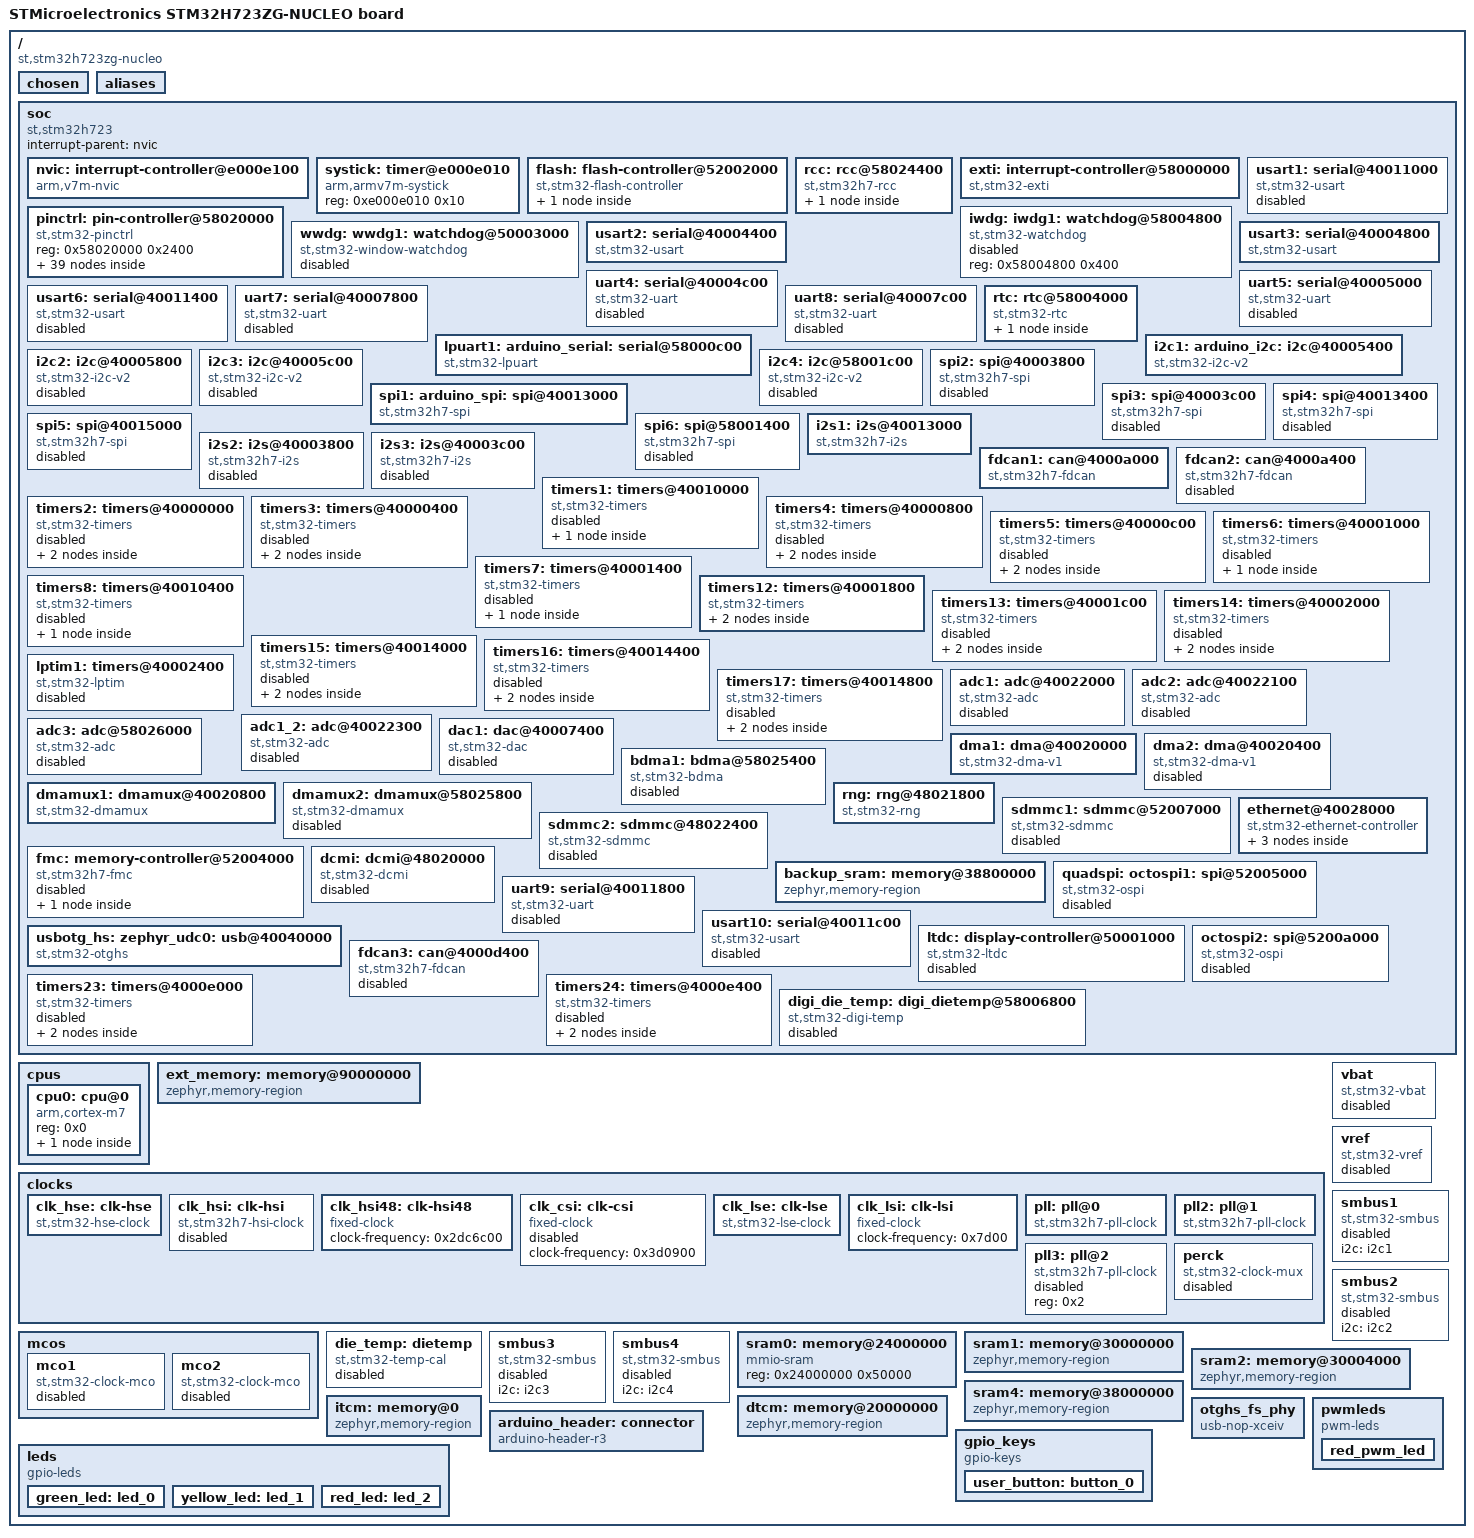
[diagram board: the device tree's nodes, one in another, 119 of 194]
/dts-v1/;

/* node '/' defined in zephyr\dts\common\skeleton.dtsi:9 */
/ {
	#address-cells = < 0x1 >;                              /* in zephyr\dts\common\skeleton.dtsi:10 */
	#size-cells = < 0x1 >;                                 /* in zephyr\dts\common\skeleton.dtsi:11 */
	model = "STMicroelectronics STM32H723ZG-NUCLEO board"; /* in zephyr\boards\st\nucleo_h723zg\nucleo_h723zg.dts:18 */
	compatible = "st,stm32h723zg-nucleo";                  /* in zephyr\boards\st\nucleo_h723zg\nucleo_h723zg.dts:19 */

	/* node '/chosen' defined in zephyr\dts\common\skeleton.dtsi:12 */
	chosen {
		zephyr,entropy = &rng;            /* in zephyr\dts\arm\st\h7\stm32h7.dtsi:27 */
		zephyr,flash-controller = &flash; /* in zephyr\dts\arm\st\h7\stm32h7.dtsi:28 */
		zephyr,console = &usart3;         /* in zephyr\boards\st\nucleo_h723zg\nucleo_h723zg.dts:22 */
		zephyr,shell-uart = &usart3;      /* in zephyr\boards\st\nucleo_h723zg\nucleo_h723zg.dts:23 */
		zephyr,dtcm = &dtcm;              /* in zephyr\boards\st\nucleo_h723zg\nucleo_h723zg.dts:24 */
		zephyr,sram = &sram0;             /* in zephyr\boards\st\nucleo_h723zg\nucleo_h723zg.dts:25 */
		zephyr,flash = &flash0;           /* in zephyr\boards\st\nucleo_h723zg\nucleo_h723zg.dts:26 */
		zephyr,canbus = &fdcan1;          /* in zephyr\boards\st\nucleo_h723zg\nucleo_h723zg.dts:27 */
	};

	/* node '/aliases' defined in zephyr\dts\common\skeleton.dtsi:13 */
	aliases {
		led0 = &green_led;       /* in zephyr\boards\st\nucleo_h723zg\nucleo_h723zg.dts:69 */
		led1 = &yellow_led;      /* in zephyr\boards\st\nucleo_h723zg\nucleo_h723zg.dts:70 */
		led2 = &red_led;         /* in zephyr\boards\st\nucleo_h723zg\nucleo_h723zg.dts:71 */
		pwm-led0 = &red_pwm_led; /* in zephyr\boards\st\nucleo_h723zg\nucleo_h723zg.dts:72 */
		sw0 = &user_button;      /* in zephyr\boards\st\nucleo_h723zg\nucleo_h723zg.dts:73 */
	};

	/* node '/soc' defined in zephyr\dts\arm\armv7-m.dtsi:6 */
	soc {
		#address-cells = < 0x1 >;     /* in zephyr\dts\arm\armv7-m.dtsi:7 */
		#size-cells = < 0x1 >;        /* in zephyr\dts\arm\armv7-m.dtsi:8 */
		interrupt-parent = < &nvic >; /* in zephyr\dts\arm\armv7-m.dtsi:10 */
		ranges;                       /* in zephyr\dts\arm\armv7-m.dtsi:11 */
		compatible = "st,stm32h723",
		             "st,stm32h7",
		             "simple-bus";    /* in zephyr\dts\arm\st\h7\stm32h723.dtsi:15 */

		/* node '/soc/interrupt-controller@e000e100' defined in zephyr\dts\arm\armv7-m.dtsi:13 */
		nvic: interrupt-controller@e000e100 {
			#address-cells = < 0x1 >;            /* in zephyr\dts\arm\armv7-m.dtsi:14 */
			compatible = "arm,v7m-nvic";         /* in zephyr\dts\arm\armv7-m.dtsi:15 */
			reg = < 0xe000e100 0xc00 >;          /* in zephyr\dts\arm\armv7-m.dtsi:16 */
			interrupt-controller;                /* in zephyr\dts\arm\armv7-m.dtsi:17 */
			#interrupt-cells = < 0x2 >;          /* in zephyr\dts\arm\armv7-m.dtsi:18 */
			arm,num-irq-priority-bits = < 0x4 >; /* in zephyr\dts\arm\st\h7\stm32h7.dtsi:1157 */
			phandle = < 0x1 >;                   /* in zephyr\dts\arm\armv7-m.dtsi:10 */
		};

		/* node '/soc/timer@e000e010' defined in zephyr\dts\arm\armv7-m.dtsi:21 */
		systick: timer@e000e010 {
			compatible = "arm,armv7m-systick"; /* in zephyr\dts\arm\armv7-m.dtsi:22 */
			reg = < 0xe000e010 0x10 >;         /* in zephyr\dts\arm\armv7-m.dtsi:23 */
		};

		/* node '/soc/flash-controller@52002000' defined in zephyr\dts\arm\st\h7\stm32h7.dtsi:144 */
		flash: flash-controller@52002000 {
			compatible = "st,stm32-flash-controller",
			             "st,stm32h7-flash-controller"; /* in zephyr\dts\arm\st\h7\stm32h7.dtsi:145 */
			reg = < 0x52002000 0x400 >;                 /* in zephyr\dts\arm\st\h7\stm32h7.dtsi:146 */
			interrupts = < 0x4 0x0 >;                   /* in zephyr\dts\arm\st\h7\stm32h7.dtsi:147 */
			#address-cells = < 0x1 >;                   /* in zephyr\dts\arm\st\h7\stm32h7.dtsi:149 */
			#size-cells = < 0x1 >;                      /* in zephyr\dts\arm\st\h7\stm32h7.dtsi:150 */

			/* node '/soc/flash-controller@52002000/flash@8000000' defined in zephyr\dts\arm\st\h7\stm32h723.dtsi:18 */
			flash0: flash@8000000 {
				compatible = "st,stm32-nv-flash",
				             "soc-nv-flash";      /* in zephyr\dts\arm\st\h7\stm32h723.dtsi:19 */
				write-block-size = < 0x20 >;      /* in zephyr\dts\arm\st\h7\stm32h723.dtsi:20 */
				erase-block-size = < 0x20000 >;   /* in zephyr\dts\arm\st\h7\stm32h723.dtsi:21 */
				max-erase-time = < 0xfa0 >;       /* in zephyr\dts\arm\st\h7\stm32h723.dtsi:23 */
				reg = < 0x8000000 0x100000 >;     /* in zephyr\dts\arm\st\h7\stm32h723Xg.dtsi:14 */
			};
		};

		/* node '/soc/rcc@58024400' defined in zephyr\dts\arm\st\h7\stm32h7.dtsi:153 */
		rcc: rcc@58024400 {
			compatible = "st,stm32h7-rcc";    /* in zephyr\dts\arm\st\h7\stm32h7.dtsi:154 */
			#clock-cells = < 0x2 >;           /* in zephyr\dts\arm\st\h7\stm32h7.dtsi:155 */
			reg = < 0x58024400 0x400 >;       /* in zephyr\dts\arm\st\h7\stm32h7.dtsi:156 */
			clocks = < &pll >;                /* in zephyr\boards\st\nucleo_h723zg\nucleo_h723zg.dts:116 */
			clock-frequency = < 0x20c85580 >; /* in zephyr\boards\st\nucleo_h723zg\nucleo_h723zg.dts:117 */
			d1cpre = < 0x1 >;                 /* in zephyr\boards\st\nucleo_h723zg\nucleo_h723zg.dts:118 */
			hpre = < 0x2 >;                   /* in zephyr\boards\st\nucleo_h723zg\nucleo_h723zg.dts:119 */
			d1ppre = < 0x2 >;                 /* in zephyr\boards\st\nucleo_h723zg\nucleo_h723zg.dts:120 */
			d2ppre1 = < 0x2 >;                /* in zephyr\boards\st\nucleo_h723zg\nucleo_h723zg.dts:121 */
			d2ppre2 = < 0x2 >;                /* in zephyr\boards\st\nucleo_h723zg\nucleo_h723zg.dts:122 */
			d3ppre = < 0x2 >;                 /* in zephyr\boards\st\nucleo_h723zg\nucleo_h723zg.dts:123 */
			phandle = < 0x3 >;                /* in zephyr\dts\arm\st\h7\stm32h7.dtsi:170 */

			/* node '/soc/rcc@58024400/reset-controller' defined in zephyr\dts\arm\st\h7\stm32h7.dtsi:158 */
			rctl: reset-controller {
				compatible = "st,stm32-rcc-rctl"; /* in zephyr\dts\arm\st\h7\stm32h7.dtsi:159 */
				#reset-cells = < 0x1 >;           /* in zephyr\dts\arm\st\h7\stm32h7.dtsi:160 */
				phandle = < 0x4 >;                /* in zephyr\dts\arm\st\h7\stm32h7.dtsi:293 */
			};
		};

		/* node '/soc/interrupt-controller@58000000' defined in zephyr\dts\arm\st\h7\stm32h7.dtsi:164 */
		exti: interrupt-controller@58000000 {
			compatible = "st,stm32-exti";  /* in zephyr\dts\arm\st\h7\stm32h7.dtsi:165 */
			interrupt-controller;          /* in zephyr\dts\arm\st\h7\stm32h7.dtsi:166 */
			#interrupt-cells = < 0x1 >;    /* in zephyr\dts\arm\st\h7\stm32h7.dtsi:167 */
			#address-cells = < 0x1 >;      /* in zephyr\dts\arm\st\h7\stm32h7.dtsi:168 */
			reg = < 0x58000000 0x400 >;    /* in zephyr\dts\arm\st\h7\stm32h7.dtsi:169 */
			clocks = < &rcc 0xf4 0x2 >;    /* in zephyr\dts\arm\st\h7\stm32h7.dtsi:170 */
			num-lines = < 0x60 >;          /* in zephyr\dts\arm\st\h7\stm32h7.dtsi:171 */
			interrupts = < 0x6 0x0 >,
			             < 0x7 0x0 >,
			             < 0x8 0x0 >,
			             < 0x9 0x0 >,
			             < 0xa 0x0 >,
			             < 0x17 0x0 >,
			             < 0x28 0x0 >;     /* in zephyr\dts\arm\st\h7\stm32h7.dtsi:172 */
			interrupt-names = "line0",
			                  "line1",
			                  "line2",
			                  "line3",
			                  "line4",
			                  "line5-9",
			                  "line10-15"; /* in zephyr\dts\arm\st\h7\stm32h7.dtsi:174 */
			line-ranges = < 0x0 0x1 >,
			              < 0x1 0x1 >,
			              < 0x2 0x1 >,
			              < 0x3 0x1 >,
			              < 0x4 0x1 >,
			              < 0x5 0x5 >,
			              < 0xa 0x6 >;     /* in zephyr\dts\arm\st\h7\stm32h7.dtsi:176 */
		};

		/* node '/soc/pin-controller@58020000' defined in zephyr\dts\arm\st\h7\stm32h7.dtsi:180 */
		pinctrl: pin-controller@58020000 {
			compatible = "st,stm32-pinctrl"; /* in zephyr\dts\arm\st\h7\stm32h7.dtsi:181 */
			#address-cells = < 0x1 >;        /* in zephyr\dts\arm\st\h7\stm32h7.dtsi:182 */
			#size-cells = < 0x1 >;           /* in zephyr\dts\arm\st\h7\stm32h7.dtsi:183 */
			reg = < 0x58020000 0x2400 >;     /* in zephyr\dts\arm\st\h7\stm32h7.dtsi:184 */

			/* node '/soc/pin-controller@58020000/gpio@58020000' defined in zephyr\dts\arm\st\h7\stm32h7.dtsi:186 */
			gpioa: gpio@58020000 {
				compatible = "st,stm32-gpio"; /* in zephyr\dts\arm\st\h7\stm32h7.dtsi:187 */
				gpio-controller;              /* in zephyr\dts\arm\st\h7\stm32h7.dtsi:188 */
				#gpio-cells = < 0x2 >;        /* in zephyr\dts\arm\st\h7\stm32h7.dtsi:189 */
				reg = < 0x58020000 0x400 >;   /* in zephyr\dts\arm\st\h7\stm32h7.dtsi:190 */
				clocks = < &rcc 0xe0 0x1 >;   /* in zephyr\dts\arm\st\h7\stm32h7.dtsi:191 */
				phandle = < 0x2c >;           /* in zephyr\boards\st\nucleo_h723zg\arduino_r3_connector.dtsi:12 */
			};

			/* node '/soc/pin-controller@58020000/gpio@58020400' defined in zephyr\dts\arm\st\h7\stm32h7.dtsi:194 */
			gpiob: gpio@58020400 {
				compatible = "st,stm32-gpio"; /* in zephyr\dts\arm\st\h7\stm32h7.dtsi:195 */
				gpio-controller;              /* in zephyr\dts\arm\st\h7\stm32h7.dtsi:196 */
				#gpio-cells = < 0x2 >;        /* in zephyr\dts\arm\st\h7\stm32h7.dtsi:197 */
				reg = < 0x58020400 0x400 >;   /* in zephyr\dts\arm\st\h7\stm32h7.dtsi:198 */
				clocks = < &rcc 0xe0 0x2 >;   /* in zephyr\dts\arm\st\h7\stm32h7.dtsi:199 */
				phandle = < 0x2e >;           /* in zephyr\boards\st\nucleo_h723zg\arduino_r3_connector.dtsi:12 */
			};

			/* node '/soc/pin-controller@58020000/gpio@58020800' defined in zephyr\dts\arm\st\h7\stm32h7.dtsi:202 */
			gpioc: gpio@58020800 {
				compatible = "st,stm32-gpio"; /* in zephyr\dts\arm\st\h7\stm32h7.dtsi:203 */
				gpio-controller;              /* in zephyr\dts\arm\st\h7\stm32h7.dtsi:204 */
				#gpio-cells = < 0x2 >;        /* in zephyr\dts\arm\st\h7\stm32h7.dtsi:205 */
				reg = < 0x58020800 0x400 >;   /* in zephyr\dts\arm\st\h7\stm32h7.dtsi:206 */
				clocks = < &rcc 0xe0 0x4 >;   /* in zephyr\dts\arm\st\h7\stm32h7.dtsi:207 */
				phandle = < 0x2d >;           /* in zephyr\boards\st\nucleo_h723zg\arduino_r3_connector.dtsi:12 */
			};

			/* node '/soc/pin-controller@58020000/gpio@58020C00' defined in zephyr\dts\arm\st\h7\stm32h7.dtsi:210 */
			gpiod: gpio@58020C00 {
				compatible = "st,stm32-gpio"; /* in zephyr\dts\arm\st\h7\stm32h7.dtsi:211 */
				gpio-controller;              /* in zephyr\dts\arm\st\h7\stm32h7.dtsi:212 */
				#gpio-cells = < 0x2 >;        /* in zephyr\dts\arm\st\h7\stm32h7.dtsi:213 */
				reg = < 0x58020c00 0x400 >;   /* in zephyr\dts\arm\st\h7\stm32h7.dtsi:214 */
				clocks = < &rcc 0xe0 0x8 >;   /* in zephyr\dts\arm\st\h7\stm32h7.dtsi:215 */
				phandle = < 0x10 >;           /* in zephyr\boards\st\nucleo_h723zg\nucleo_h723zg.dts:157 */
			};

			/* node '/soc/pin-controller@58020000/gpio@58021000' defined in zephyr\dts\arm\st\h7\stm32h7.dtsi:218 */
			gpioe: gpio@58021000 {
				compatible = "st,stm32-gpio"; /* in zephyr\dts\arm\st\h7\stm32h7.dtsi:219 */
				gpio-controller;              /* in zephyr\dts\arm\st\h7\stm32h7.dtsi:220 */
				#gpio-cells = < 0x2 >;        /* in zephyr\dts\arm\st\h7\stm32h7.dtsi:221 */
				reg = < 0x58021000 0x400 >;   /* in zephyr\dts\arm\st\h7\stm32h7.dtsi:222 */
				clocks = < &rcc 0xe0 0x10 >;  /* in zephyr\dts\arm\st\h7\stm32h7.dtsi:223 */
				phandle = < 0x31 >;           /* in zephyr\boards\st\nucleo_h723zg\arduino_r3_connector.dtsi:12 */
			};

			/* node '/soc/pin-controller@58020000/gpio@58021400' defined in zephyr\dts\arm\st\h7\stm32h7.dtsi:226 */
			gpiof: gpio@58021400 {
				compatible = "st,stm32-gpio"; /* in zephyr\dts\arm\st\h7\stm32h7.dtsi:227 */
				gpio-controller;              /* in zephyr\dts\arm\st\h7\stm32h7.dtsi:228 */
				#gpio-cells = < 0x2 >;        /* in zephyr\dts\arm\st\h7\stm32h7.dtsi:229 */
				reg = < 0x58021400 0x400 >;   /* in zephyr\dts\arm\st\h7\stm32h7.dtsi:230 */
				clocks = < &rcc 0xe0 0x20 >;  /* in zephyr\dts\arm\st\h7\stm32h7.dtsi:231 */
				phandle = < 0x2f >;           /* in zephyr\boards\st\nucleo_h723zg\arduino_r3_connector.dtsi:12 */
			};

			/* node '/soc/pin-controller@58020000/gpio@58021800' defined in zephyr\dts\arm\st\h7\stm32h7.dtsi:234 */
			gpiog: gpio@58021800 {
				compatible = "st,stm32-gpio"; /* in zephyr\dts\arm\st\h7\stm32h7.dtsi:235 */
				gpio-controller;              /* in zephyr\dts\arm\st\h7\stm32h7.dtsi:236 */
				#gpio-cells = < 0x2 >;        /* in zephyr\dts\arm\st\h7\stm32h7.dtsi:237 */
				reg = < 0x58021800 0x400 >;   /* in zephyr\dts\arm\st\h7\stm32h7.dtsi:238 */
				clocks = < &rcc 0xe0 0x40 >;  /* in zephyr\dts\arm\st\h7\stm32h7.dtsi:239 */
				phandle = < 0x30 >;           /* in zephyr\boards\st\nucleo_h723zg\arduino_r3_connector.dtsi:12 */
			};

			/* node '/soc/pin-controller@58020000/gpio@58021C00' defined in zephyr\dts\arm\st\h7\stm32h7.dtsi:242 */
			gpioh: gpio@58021C00 {
				compatible = "st,stm32-gpio"; /* in zephyr\dts\arm\st\h7\stm32h7.dtsi:243 */
				gpio-controller;              /* in zephyr\dts\arm\st\h7\stm32h7.dtsi:244 */
				#gpio-cells = < 0x2 >;        /* in zephyr\dts\arm\st\h7\stm32h7.dtsi:245 */
				reg = < 0x58021c00 0x400 >;   /* in zephyr\dts\arm\st\h7\stm32h7.dtsi:246 */
				clocks = < &rcc 0xe0 0x80 >;  /* in zephyr\dts\arm\st\h7\stm32h7.dtsi:247 */
			};

			/* node '/soc/pin-controller@58020000/gpio@58022000' defined in zephyr\dts\arm\st\h7\stm32h7.dtsi:250 */
			gpioi: gpio@58022000 {
				compatible = "st,stm32-gpio"; /* in zephyr\dts\arm\st\h7\stm32h7.dtsi:251 */
				gpio-controller;              /* in zephyr\dts\arm\st\h7\stm32h7.dtsi:252 */
				#gpio-cells = < 0x2 >;        /* in zephyr\dts\arm\st\h7\stm32h7.dtsi:253 */
				reg = < 0x58022000 0x400 >;   /* in zephyr\dts\arm\st\h7\stm32h7.dtsi:254 */
				clocks = < &rcc 0xe0 0x100 >; /* in zephyr\dts\arm\st\h7\stm32h7.dtsi:255 */
			};

			/* node '/soc/pin-controller@58020000/gpio@58022400' defined in zephyr\dts\arm\st\h7\stm32h7.dtsi:258 */
			gpioj: gpio@58022400 {
				compatible = "st,stm32-gpio"; /* in zephyr\dts\arm\st\h7\stm32h7.dtsi:259 */
				gpio-controller;              /* in zephyr\dts\arm\st\h7\stm32h7.dtsi:260 */
				#gpio-cells = < 0x2 >;        /* in zephyr\dts\arm\st\h7\stm32h7.dtsi:261 */
				reg = < 0x58022400 0x400 >;   /* in zephyr\dts\arm\st\h7\stm32h7.dtsi:262 */
				clocks = < &rcc 0xe0 0x200 >; /* in zephyr\dts\arm\st\h7\stm32h7.dtsi:263 */
			};

			/* node '/soc/pin-controller@58020000/gpio@58022800' defined in zephyr\dts\arm\st\h7\stm32h7.dtsi:266 */
			gpiok: gpio@58022800 {
				compatible = "st,stm32-gpio"; /* in zephyr\dts\arm\st\h7\stm32h7.dtsi:267 */
				gpio-controller;              /* in zephyr\dts\arm\st\h7\stm32h7.dtsi:268 */
				#gpio-cells = < 0x2 >;        /* in zephyr\dts\arm\st\h7\stm32h7.dtsi:269 */
				reg = < 0x58022800 0x400 >;   /* in zephyr\dts\arm\st\h7\stm32h7.dtsi:270 */
				clocks = < &rcc 0xe0 0x400 >; /* in zephyr\dts\arm\st\h7\stm32h7.dtsi:271 */
			};

			/* node '/soc/pin-controller@58020000/eth_ref_clk_pa1' defined in modules\hal\stm32\dts\st\h7\stm32h723zgtx-pinctrl.dtsi:1148 */
			eth_ref_clk_pa1: eth_ref_clk_pa1 {
				pinmux = < 0x2b >;             /* in modules\hal\stm32\dts\st\h7\stm32h723zgtx-pinctrl.dtsi:1149 */
				slew-rate = "very-high-speed"; /* in modules\hal\stm32\dts\st\h7\stm32h723zgtx-pinctrl.dtsi:1150 */
				phandle = < 0x18 >;            /* in zephyr\boards\st\nucleo_h723zg\nucleo_h723zg.dts:184 */
			};

			/* node '/soc/pin-controller@58020000/eth_mdio_pa2' defined in modules\hal\stm32\dts\st\h7\stm32h723zgtx-pinctrl.dtsi:1158 */
			eth_mdio_pa2: eth_mdio_pa2 {
				pinmux = < 0x4b >;             /* in modules\hal\stm32\dts\st\h7\stm32h723zgtx-pinctrl.dtsi:1159 */
				slew-rate = "very-high-speed"; /* in modules\hal\stm32\dts\st\h7\stm32h723zgtx-pinctrl.dtsi:1160 */
				phandle = < 0x20 >;            /* in zephyr\boards\st\nucleo_h723zg\nucleo_h723zg.dts:198 */
			};

			/* node '/soc/pin-controller@58020000/eth_crs_dv_pa7' defined in modules\hal\stm32\dts\st\h7\stm32h723zgtx-pinctrl.dtsi:1168 */
			eth_crs_dv_pa7: eth_crs_dv_pa7 {
				pinmux = < 0xeb >;             /* in modules\hal\stm32\dts\st\h7\stm32h723zgtx-pinctrl.dtsi:1169 */
				slew-rate = "very-high-speed"; /* in modules\hal\stm32\dts\st\h7\stm32h723zgtx-pinctrl.dtsi:1170 */
				phandle = < 0x19 >;            /* in zephyr\boards\st\nucleo_h723zg\nucleo_h723zg.dts:184 */
			};

			/* node '/soc/pin-controller@58020000/eth_txd1_pb13' defined in modules\hal\stm32\dts\st\h7\stm32h723zgtx-pinctrl.dtsi:1213 */
			eth_txd1_pb13: eth_txd1_pb13 {
				pinmux = < 0x3ab >;            /* in modules\hal\stm32\dts\st\h7\stm32h723zgtx-pinctrl.dtsi:1214 */
				slew-rate = "very-high-speed"; /* in modules\hal\stm32\dts\st\h7\stm32h723zgtx-pinctrl.dtsi:1215 */
				phandle = < 0x1e >;            /* in zephyr\boards\st\nucleo_h723zg\nucleo_h723zg.dts:184 */
			};

			/* node '/soc/pin-controller@58020000/eth_mdc_pc1' defined in modules\hal\stm32\dts\st\h7\stm32h723zgtx-pinctrl.dtsi:1218 */
			eth_mdc_pc1: eth_mdc_pc1 {
				pinmux = < 0x42b >;            /* in modules\hal\stm32\dts\st\h7\stm32h723zgtx-pinctrl.dtsi:1219 */
				slew-rate = "very-high-speed"; /* in modules\hal\stm32\dts\st\h7\stm32h723zgtx-pinctrl.dtsi:1220 */
				phandle = < 0x21 >;            /* in zephyr\boards\st\nucleo_h723zg\nucleo_h723zg.dts:198 */
			};

			/* node '/soc/pin-controller@58020000/eth_rxd0_pc4' defined in modules\hal\stm32\dts\st\h7\stm32h723zgtx-pinctrl.dtsi:1233 */
			eth_rxd0_pc4: eth_rxd0_pc4 {
				pinmux = < 0x48b >;            /* in modules\hal\stm32\dts\st\h7\stm32h723zgtx-pinctrl.dtsi:1234 */
				slew-rate = "very-high-speed"; /* in modules\hal\stm32\dts\st\h7\stm32h723zgtx-pinctrl.dtsi:1235 */
				phandle = < 0x1a >;            /* in zephyr\boards\st\nucleo_h723zg\nucleo_h723zg.dts:184 */
			};

			/* node '/soc/pin-controller@58020000/eth_rxd1_pc5' defined in modules\hal\stm32\dts\st\h7\stm32h723zgtx-pinctrl.dtsi:1238 */
			eth_rxd1_pc5: eth_rxd1_pc5 {
				pinmux = < 0x4ab >;            /* in modules\hal\stm32\dts\st\h7\stm32h723zgtx-pinctrl.dtsi:1239 */
				slew-rate = "very-high-speed"; /* in modules\hal\stm32\dts\st\h7\stm32h723zgtx-pinctrl.dtsi:1240 */
				phandle = < 0x1b >;            /* in zephyr\boards\st\nucleo_h723zg\nucleo_h723zg.dts:184 */
			};

			/* node '/soc/pin-controller@58020000/eth_tx_en_pg11' defined in modules\hal\stm32\dts\st\h7\stm32h723zgtx-pinctrl.dtsi:1253 */
			eth_tx_en_pg11: eth_tx_en_pg11 {
				pinmux = < 0xd6b >;            /* in modules\hal\stm32\dts\st\h7\stm32h723zgtx-pinctrl.dtsi:1254 */
				slew-rate = "very-high-speed"; /* in modules\hal\stm32\dts\st\h7\stm32h723zgtx-pinctrl.dtsi:1255 */
				phandle = < 0x1c >;            /* in zephyr\boards\st\nucleo_h723zg\nucleo_h723zg.dts:184 */
			};

			/* node '/soc/pin-controller@58020000/eth_txd0_pg13' defined in modules\hal\stm32\dts\st\h7\stm32h723zgtx-pinctrl.dtsi:1263 */
			eth_txd0_pg13: eth_txd0_pg13 {
				pinmux = < 0xdab >;            /* in modules\hal\stm32\dts\st\h7\stm32h723zgtx-pinctrl.dtsi:1264 */
				slew-rate = "very-high-speed"; /* in modules\hal\stm32\dts\st\h7\stm32h723zgtx-pinctrl.dtsi:1265 */
				phandle = < 0x1d >;            /* in zephyr\boards\st\nucleo_h723zg\nucleo_h723zg.dts:184 */
			};

			/* node '/soc/pin-controller@58020000/fdcan1_rx_pd0' defined in modules\hal\stm32\dts\st\h7\stm32h723zgtx-pinctrl.dtsi:1283 */
			fdcan1_rx_pd0: fdcan1_rx_pd0 {
				pinmux = < 0x609 >; /* in modules\hal\stm32\dts\st\h7\stm32h723zgtx-pinctrl.dtsi:1284 */
				phandle = < 0x15 >; /* in zephyr\boards\st\nucleo_h723zg\nucleo_h723zg.dts:218 */
			};

			/* node '/soc/pin-controller@58020000/fdcan1_tx_pd1' defined in modules\hal\stm32\dts\st\h7\stm32h723zgtx-pinctrl.dtsi:1317 */
			fdcan1_tx_pd1: fdcan1_tx_pd1 {
				pinmux = < 0x629 >; /* in modules\hal\stm32\dts\st\h7\stm32h723zgtx-pinctrl.dtsi:1318 */
				phandle = < 0x16 >; /* in zephyr\boards\st\nucleo_h723zg\nucleo_h723zg.dts:218 */
			};

			/* node '/soc/pin-controller@58020000/i2c1_scl_pb8' defined in modules\hal\stm32\dts\st\h7\stm32h723zgtx-pinctrl.dtsi:1843 */
			i2c1_scl_pb8: i2c1_scl_pb8 {
				pinmux = < 0x304 >; /* in modules\hal\stm32\dts\st\h7\stm32h723zgtx-pinctrl.dtsi:1844 */
				bias-pull-up;       /* in modules\hal\stm32\dts\st\h7\stm32h723zgtx-pinctrl.dtsi:1845 */
				drive-open-drain;   /* in modules\hal\stm32\dts\st\h7\stm32h723zgtx-pinctrl.dtsi:1846 */
				phandle = < 0xb >;  /* in zephyr\boards\st\nucleo_h723zg\nucleo_h723zg.dts:161 */
			};

			/* node '/soc/pin-controller@58020000/i2c1_sda_pb9' defined in modules\hal\stm32\dts\st\h7\stm32h723zgtx-pinctrl.dtsi:1917 */
			i2c1_sda_pb9: i2c1_sda_pb9 {
				pinmux = < 0x324 >; /* in modules\hal\stm32\dts\st\h7\stm32h723zgtx-pinctrl.dtsi:1918 */
				bias-pull-up;       /* in modules\hal\stm32\dts\st\h7\stm32h723zgtx-pinctrl.dtsi:1919 */
				drive-open-drain;   /* in modules\hal\stm32\dts\st\h7\stm32h723zgtx-pinctrl.dtsi:1920 */
				phandle = < 0xc >;  /* in zephyr\boards\st\nucleo_h723zg\nucleo_h723zg.dts:161 */
			};

			/* node '/soc/pin-controller@58020000/i2s1_ck_pa5' defined in modules\hal\stm32\dts\st\h7\stm32h723zgtx-pinctrl.dtsi:2042 */
			i2s1_ck_pa5: i2s1_ck_pa5 {
				pinmux = < 0xa5 >;             /* in modules\hal\stm32\dts\st\h7\stm32h723zgtx-pinctrl.dtsi:2043 */
				slew-rate = "very-high-speed"; /* in modules\hal\stm32\dts\st\h7\stm32h723zgtx-pinctrl.dtsi:2044 */
				phandle = < 0x11 >;            /* in template_zephyr\boards\nucleo_h723zg.overlay:12 */
			};

			/* node '/soc/pin-controller@58020000/i2s1_ws_pa4' defined in modules\hal\stm32\dts\st\h7\stm32h723zgtx-pinctrl.dtsi:2136 */
			i2s1_ws_pa4: i2s1_ws_pa4 {
				pinmux = < 0x85 >;  /* in modules\hal\stm32\dts\st\h7\stm32h723zgtx-pinctrl.dtsi:2137 */
				phandle = < 0x12 >; /* in template_zephyr\boards\nucleo_h723zg.overlay:12 */
			};

			/* node '/soc/pin-controller@58020000/sai1_sd_a_pb2' defined in modules\hal\stm32\dts\st\h7\stm32h723zgtx-pinctrl.dtsi:2809 */
			sai1_sd_a_pb2: sai1_sd_a_pb2 {
				pinmux = < 0x246 >; /* in modules\hal\stm32\dts\st\h7\stm32h723zgtx-pinctrl.dtsi:2810 */
				phandle = < 0x13 >; /* in template_zephyr\boards\nucleo_h723zg.overlay:12 */
			};

			/* node '/soc/pin-controller@58020000/spi1_miso_pa6' defined in modules\hal\stm32\dts\st\h7\stm32h723zgtx-pinctrl.dtsi:3253 */
			spi1_miso_pa6: spi1_miso_pa6 {
				pinmux = < 0xc5 >; /* in modules\hal\stm32\dts\st\h7\stm32h723zgtx-pinctrl.dtsi:3254 */
				bias-pull-down;    /* in modules\hal\stm32\dts\st\h7\stm32h723zgtx-pinctrl.dtsi:3255 */
				phandle = < 0xe >; /* in zephyr\boards\st\nucleo_h723zg\nucleo_h723zg.dts:155 */
			};

			/* node '/soc/pin-controller@58020000/spi1_mosi_pb5' defined in modules\hal\stm32\dts\st\h7\stm32h723zgtx-pinctrl.dtsi:3325 */
			spi1_mosi_pb5: spi1_mosi_pb5 {
				pinmux = < 0x2a5 >; /* in modules\hal\stm32\dts\st\h7\stm32h723zgtx-pinctrl.dtsi:3326 */
				bias-pull-down;     /* in modules\hal\stm32\dts\st\h7\stm32h723zgtx-pinctrl.dtsi:3327 */
				phandle = < 0xf >;  /* in zephyr\boards\st\nucleo_h723zg\nucleo_h723zg.dts:155 */
			};

			/* node '/soc/pin-controller@58020000/spi1_sck_pa5' defined in modules\hal\stm32\dts\st\h7\stm32h723zgtx-pinctrl.dtsi:3489 */
			spi1_sck_pa5: spi1_sck_pa5 {
				pinmux = < 0xa5 >;             /* in modules\hal\stm32\dts\st\h7\stm32h723zgtx-pinctrl.dtsi:3490 */
				bias-pull-down;                /* in modules\hal\stm32\dts\st\h7\stm32h723zgtx-pinctrl.dtsi:3491 */
				slew-rate = "very-high-speed"; /* in modules\hal\stm32\dts\st\h7\stm32h723zgtx-pinctrl.dtsi:3492 */
				phandle = < 0xd >;             /* in zephyr\boards\st\nucleo_h723zg\nucleo_h723zg.dts:155 */
			};

			/* node '/soc/pin-controller@58020000/tim12_ch1_pb14' defined in modules\hal\stm32\dts\st\h7\stm32h723zgtx-pinctrl.dtsi:3767 */
			tim12_ch1_pb14: tim12_ch1_pb14 {
				pinmux = < 0x3c2 >; /* in modules\hal\stm32\dts\st\h7\stm32h723zgtx-pinctrl.dtsi:3768 */
				phandle = < 0x17 >; /* in zephyr\boards\st\nucleo_h723zg\nucleo_h723zg.dts:177 */
			};

			/* node '/soc/pin-controller@58020000/lpuart1_rx_pb7' defined in modules\hal\stm32\dts\st\h7\stm32h723zgtx-pinctrl.dtsi:4303 */
			lpuart1_rx_pb7: lpuart1_rx_pb7 {
				pinmux = < 0x2e8 >; /* in modules\hal\stm32\dts\st\h7\stm32h723zgtx-pinctrl.dtsi:4304 */
				phandle = < 0xa >;  /* in zephyr\boards\st\nucleo_h723zg\nucleo_h723zg.dts:127 */
			};

			/* node '/soc/pin-controller@58020000/usart2_rx_pd6' defined in modules\hal\stm32\dts\st\h7\stm32h723zgtx-pinctrl.dtsi:4319 */
			usart2_rx_pd6: usart2_rx_pd6 {
				pinmux = < 0x6c7 >; /* in modules\hal\stm32\dts\st\h7\stm32h723zgtx-pinctrl.dtsi:4320 */
				phandle = < 0x6 >;  /* in zephyr\boards\st\nucleo_h723zg\nucleo_h723zg.dts:141 */
			};

			/* node '/soc/pin-controller@58020000/usart3_rx_pd9' defined in modules\hal\stm32\dts\st\h7\stm32h723zgtx-pinctrl.dtsi:4331 */
			usart3_rx_pd9: usart3_rx_pd9 {
				pinmux = < 0x727 >; /* in modules\hal\stm32\dts\st\h7\stm32h723zgtx-pinctrl.dtsi:4332 */
				phandle = < 0x8 >;  /* in zephyr\boards\st\nucleo_h723zg\nucleo_h723zg.dts:134 */
			};

			/* node '/soc/pin-controller@58020000/lpuart1_tx_pb6' defined in modules\hal\stm32\dts\st\h7\stm32h723zgtx-pinctrl.dtsi:4425 */
			lpuart1_tx_pb6: lpuart1_tx_pb6 {
				pinmux = < 0x2c8 >; /* in modules\hal\stm32\dts\st\h7\stm32h723zgtx-pinctrl.dtsi:4426 */
				bias-pull-up;       /* in modules\hal\stm32\dts\st\h7\stm32h723zgtx-pinctrl.dtsi:4427 */
				phandle = < 0x9 >;  /* in zephyr\boards\st\nucleo_h723zg\nucleo_h723zg.dts:127 */
			};

			/* node '/soc/pin-controller@58020000/usart2_tx_pd5' defined in modules\hal\stm32\dts\st\h7\stm32h723zgtx-pinctrl.dtsi:4445 */
			usart2_tx_pd5: usart2_tx_pd5 {
				pinmux = < 0x6a7 >; /* in modules\hal\stm32\dts\st\h7\stm32h723zgtx-pinctrl.dtsi:4446 */
				bias-pull-up;       /* in modules\hal\stm32\dts\st\h7\stm32h723zgtx-pinctrl.dtsi:4447 */
				phandle = < 0x5 >;  /* in zephyr\boards\st\nucleo_h723zg\nucleo_h723zg.dts:141 */
			};

			/* node '/soc/pin-controller@58020000/usart3_tx_pd8' defined in modules\hal\stm32\dts\st\h7\stm32h723zgtx-pinctrl.dtsi:4460 */
			usart3_tx_pd8: usart3_tx_pd8 {
				pinmux = < 0x707 >; /* in modules\hal\stm32\dts\st\h7\stm32h723zgtx-pinctrl.dtsi:4461 */
				bias-pull-up;       /* in modules\hal\stm32\dts\st\h7\stm32h723zgtx-pinctrl.dtsi:4462 */
				phandle = < 0x7 >;  /* in zephyr\boards\st\nucleo_h723zg\nucleo_h723zg.dts:134 */
			};

			/* node '/soc/pin-controller@58020000/usb_otg_hs_dm_pa11' defined in modules\hal\stm32\dts\st\h7\stm32h723zgtx-pinctrl.dtsi:4564 */
			usb_otg_hs_dm_pa11: usb_otg_hs_dm_pa11 {
				pinmux = < 0x170 >; /* in modules\hal\stm32\dts\st\h7\stm32h723zgtx-pinctrl.dtsi:4565 */
				phandle = < 0x24 >; /* in zephyr\boards\st\nucleo_h723zg\nucleo_h723zg.dts:208 */
			};

			/* node '/soc/pin-controller@58020000/usb_otg_hs_dp_pa12' defined in modules\hal\stm32\dts\st\h7\stm32h723zgtx-pinctrl.dtsi:4568 */
			usb_otg_hs_dp_pa12: usb_otg_hs_dp_pa12 {
				pinmux = < 0x190 >; /* in modules\hal\stm32\dts\st\h7\stm32h723zgtx-pinctrl.dtsi:4569 */
				phandle = < 0x25 >; /* in zephyr\boards\st\nucleo_h723zg\nucleo_h723zg.dts:208 */
			};
		};

		/* node '/soc/watchdog@58004800' defined in zephyr\dts\arm\st\h7\stm32h7.dtsi:275 */
		iwdg: iwdg1: watchdog@58004800 {
			compatible = "st,stm32-watchdog"; /* in zephyr\dts\arm\st\h7\stm32h7.dtsi:276 */
			reg = < 0x58004800 0x400 >;       /* in zephyr\dts\arm\st\h7\stm32h7.dtsi:277 */
			status = "disabled";              /* in zephyr\dts\arm\st\h7\stm32h7.dtsi:278 */
		};

		/* node '/soc/watchdog@50003000' defined in zephyr\dts\arm\st\h7\stm32h7.dtsi:281 */
		wwdg: wwdg1: watchdog@50003000 {
			compatible = "st,stm32-window-watchdog"; /* in zephyr\dts\arm\st\h7\stm32h7.dtsi:282 */
			reg = < 0x50003000 0x1000 >;             /* in zephyr\dts\arm\st\h7\stm32h7.dtsi:283 */
			clocks = < &rcc 0xe4 0x40 >;             /* in zephyr\dts\arm\st\h7\stm32h7.dtsi:284 */
			interrupts = < 0x0 0x7 >;                /* in zephyr\dts\arm\st\h7\stm32h7.dtsi:285 */
			status = "disabled";                     /* in zephyr\dts\arm\st\h7\stm32h7.dtsi:286 */
		};

		/* node '/soc/serial@40011000' defined in zephyr\dts\arm\st\h7\stm32h7.dtsi:289 */
		usart1: serial@40011000 {
			compatible = "st,stm32-usart",
			             "st,stm32-uart";  /* in zephyr\dts\arm\st\h7\stm32h7.dtsi:290 */
			reg = < 0x40011000 0x400 >;    /* in zephyr\dts\arm\st\h7\stm32h7.dtsi:291 */
			clocks = < &rcc 0xf0 0x10 >;   /* in zephyr\dts\arm\st\h7\stm32h7.dtsi:292 */
			resets = < &rctl 0x1304 >;     /* in zephyr\dts\arm\st\h7\stm32h7.dtsi:293 */
			interrupts = < 0x25 0x0 >;     /* in zephyr\dts\arm\st\h7\stm32h7.dtsi:294 */
			status = "disabled";           /* in zephyr\dts\arm\st\h7\stm32h7.dtsi:295 */
		};

		/* node '/soc/serial@40004400' defined in zephyr\dts\arm\st\h7\stm32h7.dtsi:297 */
		usart2: serial@40004400 {
			compatible = "st,stm32-usart",
			             "st,stm32-uart";                  /* in zephyr\dts\arm\st\h7\stm32h7.dtsi:298 */
			reg = < 0x40004400 0x400 >;                    /* in zephyr\dts\arm\st\h7\stm32h7.dtsi:299 */
			clocks = < &rcc 0xe8 0x20000 >;                /* in zephyr\dts\arm\st\h7\stm32h7.dtsi:300 */
			resets = < &rctl 0x1211 >;                     /* in zephyr\dts\arm\st\h7\stm32h7.dtsi:301 */
			interrupts = < 0x26 0x0 >;                     /* in zephyr\dts\arm\st\h7\stm32h7.dtsi:302 */
			pinctrl-0 = < &usart2_tx_pd5 &usart2_rx_pd6 >; /* in zephyr\boards\st\nucleo_h723zg\nucleo_h723zg.dts:141 */
			pinctrl-names = "default";                     /* in zephyr\boards\st\nucleo_h723zg\nucleo_h723zg.dts:142 */
			current-speed = < 0x1c200 >;                   /* in zephyr\boards\st\nucleo_h723zg\nucleo_h723zg.dts:143 */
			status = "okay";                               /* in zephyr\boards\st\nucleo_h723zg\nucleo_h723zg.dts:144 */
		};

		/* node '/soc/serial@40004800' defined in zephyr\dts\arm\st\h7\stm32h7.dtsi:305 */
		usart3: serial@40004800 {
			compatible = "st,stm32-usart",
			             "st,stm32-uart";                  /* in zephyr\dts\arm\st\h7\stm32h7.dtsi:306 */
			reg = < 0x40004800 0x400 >;                    /* in zephyr\dts\arm\st\h7\stm32h7.dtsi:307 */
			clocks = < &rcc 0xe8 0x40000 >;                /* in zephyr\dts\arm\st\h7\stm32h7.dtsi:308 */
			resets = < &rctl 0x1212 >;                     /* in zephyr\dts\arm\st\h7\stm32h7.dtsi:309 */
			interrupts = < 0x27 0x0 >;                     /* in zephyr\dts\arm\st\h7\stm32h7.dtsi:310 */
			pinctrl-0 = < &usart3_tx_pd8 &usart3_rx_pd9 >; /* in zephyr\boards\st\nucleo_h723zg\nucleo_h723zg.dts:134 */
			pinctrl-names = "default";                     /* in zephyr\boards\st\nucleo_h723zg\nucleo_h723zg.dts:135 */
			status = "okay";                               /* in template_zephyr\boards\nucleo_h723zg.overlay:21 */
			current-speed = < 0x1c200 >;                   /* in template_zephyr\boards\nucleo_h723zg.overlay:22 */
		};

		/* node '/soc/serial@40004c00' defined in zephyr\dts\arm\st\h7\stm32h7.dtsi:313 */
		uart4: serial@40004c00 {
			compatible = "st,stm32-uart";   /* in zephyr\dts\arm\st\h7\stm32h7.dtsi:314 */
			reg = < 0x40004c00 0x400 >;     /* in zephyr\dts\arm\st\h7\stm32h7.dtsi:315 */
			clocks = < &rcc 0xe8 0x80000 >; /* in zephyr\dts\arm\st\h7\stm32h7.dtsi:316 */
			resets = < &rctl 0x1213 >;      /* in zephyr\dts\arm\st\h7\stm32h7.dtsi:317 */
			interrupts = < 0x34 0x0 >;      /* in zephyr\dts\arm\st\h7\stm32h7.dtsi:318 */
			status = "disabled";            /* in zephyr\dts\arm\st\h7\stm32h7.dtsi:319 */
		};

		/* node '/soc/serial@40005000' defined in zephyr\dts\arm\st\h7\stm32h7.dtsi:321 */
		uart5: serial@40005000 {
			compatible = "st,stm32-uart";    /* in zephyr\dts\arm\st\h7\stm32h7.dtsi:322 */
			reg = < 0x40005000 0x400 >;      /* in zephyr\dts\arm\st\h7\stm32h7.dtsi:323 */
			clocks = < &rcc 0xe8 0x100000 >; /* in zephyr\dts\arm\st\h7\stm32h7.dtsi:324 */
			resets = < &rctl 0x1214 >;       /* in zephyr\dts\arm\st\h7\stm32h7.dtsi:325 */
			interrupts = < 0x35 0x0 >;       /* in zephyr\dts\arm\st\h7\stm32h7.dtsi:326 */
			status = "disabled";             /* in zephyr\dts\arm\st\h7\stm32h7.dtsi:327 */
		};

		/* node '/soc/serial@40011400' defined in zephyr\dts\arm\st\h7\stm32h7.dtsi:329 */
		usart6: serial@40011400 {
			compatible = "st,stm32-usart",
			             "st,stm32-uart";  /* in zephyr\dts\arm\st\h7\stm32h7.dtsi:330 */
			reg = < 0x40011400 0x400 >;    /* in zephyr\dts\arm\st\h7\stm32h7.dtsi:331 */
			clocks = < &rcc 0xf0 0x20 >;   /* in zephyr\dts\arm\st\h7\stm32h7.dtsi:332 */
			resets = < &rctl 0x1305 >;     /* in zephyr\dts\arm\st\h7\stm32h7.dtsi:333 */
			interrupts = < 0x47 0x0 >;     /* in zephyr\dts\arm\st\h7\stm32h7.dtsi:334 */
			status = "disabled";           /* in zephyr\dts\arm\st\h7\stm32h7.dtsi:335 */
		};

		/* node '/soc/serial@40007800' defined in zephyr\dts\arm\st\h7\stm32h7.dtsi:337 */
		uart7: serial@40007800 {
			compatible = "st,stm32-uart";      /* in zephyr\dts\arm\st\h7\stm32h7.dtsi:338 */
			reg = < 0x40007800 0x400 >;        /* in zephyr\dts\arm\st\h7\stm32h7.dtsi:339 */
			clocks = < &rcc 0xe8 0x40000000 >; /* in zephyr\dts\arm\st\h7\stm32h7.dtsi:340 */
			resets = < &rctl 0x121e >;         /* in zephyr\dts\arm\st\h7\stm32h7.dtsi:341 */
			interrupts = < 0x52 0x0 >;         /* in zephyr\dts\arm\st\h7\stm32h7.dtsi:342 */
			status = "disabled";               /* in zephyr\dts\arm\st\h7\stm32h7.dtsi:343 */
		};

		/* node '/soc/serial@40007c00' defined in zephyr\dts\arm\st\h7\stm32h7.dtsi:345 */
		uart8: serial@40007c00 {
			compatible = "st,stm32-uart";      /* in zephyr\dts\arm\st\h7\stm32h7.dtsi:346 */
			reg = < 0x40007c00 0x400 >;        /* in zephyr\dts\arm\st\h7\stm32h7.dtsi:347 */
			clocks = < &rcc 0xe8 0x80000000 >; /* in zephyr\dts\arm\st\h7\stm32h7.dtsi:348 */
			resets = < &rctl 0x121f >;         /* in zephyr\dts\arm\st\h7\stm32h7.dtsi:349 */
			interrupts = < 0x53 0x0 >;         /* in zephyr\dts\arm\st\h7\stm32h7.dtsi:350 */
			status = "disabled";               /* in zephyr\dts\arm\st\h7\stm32h7.dtsi:351 */
		};

		/* node '/soc/serial@58000c00' defined in zephyr\dts\arm\st\h7\stm32h7.dtsi:354 */
		lpuart1: arduino_serial: serial@58000c00 {
			compatible = "st,stm32-lpuart",
			             "st,stm32-uart";                    /* in zephyr\dts\arm\st\h7\stm32h7.dtsi:355 */
			reg = < 0x58000c00 0x400 >;                      /* in zephyr\dts\arm\st\h7\stm32h7.dtsi:356 */
			clocks = < &rcc 0xf4 0x8 >;                      /* in zephyr\dts\arm\st\h7\stm32h7.dtsi:357 */
			resets = < &rctl 0x1383 >;                       /* in zephyr\dts\arm\st\h7\stm32h7.dtsi:358 */
			interrupts = < 0x8e 0x0 >;                       /* in zephyr\dts\arm\st\h7\stm32h7.dtsi:359 */
			pinctrl-0 = < &lpuart1_tx_pb6 &lpuart1_rx_pb7 >; /* in zephyr\boards\st\nucleo_h723zg\nucleo_h723zg.dts:127 */
			pinctrl-names = "default";                       /* in zephyr\boards\st\nucleo_h723zg\nucleo_h723zg.dts:128 */
			current-speed = < 0x1c200 >;                     /* in zephyr\boards\st\nucleo_h723zg\nucleo_h723zg.dts:129 */
			status = "okay";                                 /* in zephyr\boards\st\nucleo_h723zg\nucleo_h723zg.dts:130 */
		};

		/* node '/soc/rtc@58004000' defined in zephyr\dts\arm\st\h7\stm32h7.dtsi:363 */
		rtc: rtc@58004000 {
			compatible = "st,stm32-rtc";      /* in zephyr\dts\arm\st\h7\stm32h7.dtsi:364 */
			reg = < 0x58004000 0x400 >;       /* in zephyr\dts\arm\st\h7\stm32h7.dtsi:365 */
			interrupts = < 0x29 0x0 >;        /* in zephyr\dts\arm\st\h7\stm32h7.dtsi:366 */
			prescaler = < 0x8000 >;           /* in zephyr\dts\arm\st\h7\stm32h7.dtsi:368 */
			alarms-count = < 0x2 >;           /* in zephyr\dts\arm\st\h7\stm32h7.dtsi:369 */
			alrm-exti-line = < 0x11 >;        /* in zephyr\dts\arm\st\h7\stm32h7.dtsi:370 */
			clocks = < &rcc 0xf4 0x10000 >,
			         < &rcc 0x3 0x10c80070 >; /* in zephyr\boards\st\nucleo_h723zg\nucleo_h723zg.dts:148 */
			status = "okay";                  /* in zephyr\boards\st\nucleo_h723zg\nucleo_h723zg.dts:150 */

			/* node '/soc/rtc@58004000/backup_regs' defined in zephyr\dts\arm\st\h7\stm32h723.dtsi:132 */
			bbram: backup_regs {
				compatible = "st,stm32-bbram"; /* in zephyr\dts\arm\st\h7\stm32h723.dtsi:133 */
				st,backup-regs = < 0x20 >;     /* in zephyr\dts\arm\st\h7\stm32h723.dtsi:134 */
				status = "disabled";           /* in zephyr\dts\arm\st\h7\stm32h723.dtsi:135 */
			};
		};

		/* node '/soc/i2c@40005400' defined in zephyr\dts\arm\st\h7\stm32h7.dtsi:374 */
		i2c1: arduino_i2c: i2c@40005400 {
			compatible = "st,stm32-i2c-v2";              /* in zephyr\dts\arm\st\h7\stm32h7.dtsi:375 */
			#address-cells = < 0x1 >;                    /* in zephyr\dts\arm\st\h7\stm32h7.dtsi:377 */
			#size-cells = < 0x0 >;                       /* in zephyr\dts\arm\st\h7\stm32h7.dtsi:378 */
			reg = < 0x40005400 0x400 >;                  /* in zephyr\dts\arm\st\h7\stm32h7.dtsi:379 */
			clocks = < &rcc 0xe8 0x200000 >;             /* in zephyr\dts\arm\st\h7\stm32h7.dtsi:380 */
			interrupts = < 0x1f 0x0 >,
			             < 0x20 0x0 >;                   /* in zephyr\dts\arm\st\h7\stm32h7.dtsi:381 */
			interrupt-names = "event",
			                  "error";                   /* in zephyr\dts\arm\st\h7\stm32h7.dtsi:382 */
			pinctrl-0 = < &i2c1_scl_pb8 &i2c1_sda_pb9 >; /* in zephyr\boards\st\nucleo_h723zg\nucleo_h723zg.dts:161 */
			pinctrl-names = "default";                   /* in zephyr\boards\st\nucleo_h723zg\nucleo_h723zg.dts:162 */
			status = "okay";                             /* in zephyr\boards\st\nucleo_h723zg\nucleo_h723zg.dts:163 */
			clock-frequency = < 0x61a80 >;               /* in zephyr\boards\st\nucleo_h723zg\nucleo_h723zg.dts:164 */
			phandle = < 0x28 >;                          /* in zephyr\dts\arm\st\h7\stm32h7.dtsi:1127 */
		};

		/* node '/soc/i2c@40005800' defined in zephyr\dts\arm\st\h7\stm32h7.dtsi:386 */
		i2c2: i2c@40005800 {
			compatible = "st,stm32-i2c-v2";  /* in zephyr\dts\arm\st\h7\stm32h7.dtsi:387 */
			clock-frequency = < 0x186a0 >;   /* in zephyr\dts\arm\st\h7\stm32h7.dtsi:388 */
			#address-cells = < 0x1 >;        /* in zephyr\dts\arm\st\h7\stm32h7.dtsi:389 */
			#size-cells = < 0x0 >;           /* in zephyr\dts\arm\st\h7\stm32h7.dtsi:390 */
			reg = < 0x40005800 0x400 >;      /* in zephyr\dts\arm\st\h7\stm32h7.dtsi:391 */
			clocks = < &rcc 0xe8 0x400000 >; /* in zephyr\dts\arm\st\h7\stm32h7.dtsi:392 */
			interrupts = < 0x21 0x0 >,
			             < 0x22 0x0 >;       /* in zephyr\dts\arm\st\h7\stm32h7.dtsi:393 */
			interrupt-names = "event",
			                  "error";       /* in zephyr\dts\arm\st\h7\stm32h7.dtsi:394 */
			status = "disabled";             /* in zephyr\dts\arm\st\h7\stm32h7.dtsi:395 */
			phandle = < 0x29 >;              /* in zephyr\dts\arm\st\h7\stm32h7.dtsi:1135 */
		};

		/* node '/soc/i2c@40005c00' defined in zephyr\dts\arm\st\h7\stm32h7.dtsi:398 */
		i2c3: i2c@40005c00 {
			compatible = "st,stm32-i2c-v2";  /* in zephyr\dts\arm\st\h7\stm32h7.dtsi:399 */
			clock-frequency = < 0x186a0 >;   /* in zephyr\dts\arm\st\h7\stm32h7.dtsi:400 */
			#address-cells = < 0x1 >;        /* in zephyr\dts\arm\st\h7\stm32h7.dtsi:401 */
			#size-cells = < 0x0 >;           /* in zephyr\dts\arm\st\h7\stm32h7.dtsi:402 */
			reg = < 0x40005c00 0x400 >;      /* in zephyr\dts\arm\st\h7\stm32h7.dtsi:403 */
			clocks = < &rcc 0xe8 0x800000 >; /* in zephyr\dts\arm\st\h7\stm32h7.dtsi:404 */
			interrupts = < 0x48 0x0 >,
			             < 0x49 0x0 >;       /* in zephyr\dts\arm\st\h7\stm32h7.dtsi:405 */
			interrupt-names = "event",
			                  "error";       /* in zephyr\dts\arm\st\h7\stm32h7.dtsi:406 */
			status = "disabled";             /* in zephyr\dts\arm\st\h7\stm32h7.dtsi:407 */
			phandle = < 0x2a >;              /* in zephyr\dts\arm\st\h7\stm32h7.dtsi:1143 */
		};

		/* node '/soc/i2c@58001c00' defined in zephyr\dts\arm\st\h7\stm32h7.dtsi:410 */
		i2c4: i2c@58001c00 {
			compatible = "st,stm32-i2c-v2"; /* in zephyr\dts\arm\st\h7\stm32h7.dtsi:411 */
			clock-frequency = < 0x186a0 >;  /* in zephyr\dts\arm\st\h7\stm32h7.dtsi:412 */
			#address-cells = < 0x1 >;       /* in zephyr\dts\arm\st\h7\stm32h7.dtsi:413 */
			#size-cells = < 0x0 >;          /* in zephyr\dts\arm\st\h7\stm32h7.dtsi:414 */
			reg = < 0x58001c00 0x400 >;     /* in zephyr\dts\arm\st\h7\stm32h7.dtsi:415 */
			clocks = < &rcc 0xf4 0x80 >;    /* in zephyr\dts\arm\st\h7\stm32h7.dtsi:416 */
			interrupts = < 0x5f 0x0 >,
			             < 0x60 0x0 >;      /* in zephyr\dts\arm\st\h7\stm32h7.dtsi:417 */
			interrupt-names = "event",
			                  "error";      /* in zephyr\dts\arm\st\h7\stm32h7.dtsi:418 */
			status = "disabled";            /* in zephyr\dts\arm\st\h7\stm32h7.dtsi:419 */
			phandle = < 0x2b >;             /* in zephyr\dts\arm\st\h7\stm32h7.dtsi:1151 */
		};

		/* node '/soc/spi@40013000' defined in zephyr\dts\arm\st\h7\stm32h7.dtsi:422 */
		spi1: arduino_spi: spi@40013000 {
			compatible = "st,stm32h7-spi",
			             "st,stm32-spi-fifo",
			             "st,stm32-spi";                                 /* in zephyr\dts\arm\st\h7\stm32h7.dtsi:423 */
			#address-cells = < 0x1 >;                                    /* in zephyr\dts\arm\st\h7\stm32h7.dtsi:424 */
			#size-cells = < 0x0 >;                                       /* in zephyr\dts\arm\st\h7\stm32h7.dtsi:425 */
			reg = < 0x40013000 0x400 >;                                  /* in zephyr\dts\arm\st\h7\stm32h7.dtsi:426 */
			clocks = < &rcc 0xf0 0x1000 >,
			         < &rcc 0x9 0x1cc0050 >;                             /* in zephyr\dts\arm\st\h7\stm32h7.dtsi:427 */
			interrupts = < 0x23 0x0 >;                                   /* in zephyr\dts\arm\st\h7\stm32h7.dtsi:429 */
			status = "okay";                                             /* in zephyr\boards\st\nucleo_h723zg\nucleo_h723zg.dts:154 */
			pinctrl-0 = < &spi1_sck_pa5 &spi1_miso_pa6 &spi1_mosi_pb5 >; /* in zephyr\boards\st\nucleo_h723zg\nucleo_h723zg.dts:155 */
			pinctrl-names = "default";                                   /* in zephyr\boards\st\nucleo_h723zg\nucleo_h723zg.dts:156 */
			cs-gpios = < &gpiod 0xe 0x11 >;                              /* in zephyr\boards\st\nucleo_h723zg\nucleo_h723zg.dts:157 */
		};

		/* node '/soc/spi@40003800' defined in zephyr\dts\arm\st\h7\stm32h7.dtsi:433 */
		spi2: spi@40003800 {
			compatible = "st,stm32h7-spi",
			             "st,stm32-spi-fifo",
			             "st,stm32-spi";      /* in zephyr\dts\arm\st\h7\stm32h7.dtsi:434 */
			#address-cells = < 0x1 >;         /* in zephyr\dts\arm\st\h7\stm32h7.dtsi:435 */
			#size-cells = < 0x0 >;            /* in zephyr\dts\arm\st\h7\stm32h7.dtsi:436 */
			reg = < 0x40003800 0x400 >;       /* in zephyr\dts\arm\st\h7\stm32h7.dtsi:437 */
			clocks = < &rcc 0xe8 0x4000 >,
			         < &rcc 0x9 0x1cc0050 >;  /* in zephyr\dts\arm\st\h7\stm32h7.dtsi:438 */
			interrupts = < 0x24 0x0 >;        /* in zephyr\dts\arm\st\h7\stm32h7.dtsi:440 */
			status = "disabled";              /* in zephyr\dts\arm\st\h7\stm32h7.dtsi:441 */
		};

		/* node '/soc/spi@40003c00' defined in zephyr\dts\arm\st\h7\stm32h7.dtsi:444 */
		spi3: spi@40003c00 {
			compatible = "st,stm32h7-spi",
			             "st,stm32-spi-fifo",
			             "st,stm32-spi";      /* in zephyr\dts\arm\st\h7\stm32h7.dtsi:445 */
			#address-cells = < 0x1 >;         /* in zephyr\dts\arm\st\h7\stm32h7.dtsi:446 */
			#size-cells = < 0x0 >;            /* in zephyr\dts\arm\st\h7\stm32h7.dtsi:447 */
			reg = < 0x40003c00 0x400 >;       /* in zephyr\dts\arm\st\h7\stm32h7.dtsi:448 */
			clocks = < &rcc 0xe8 0x8000 >,
			         < &rcc 0x9 0x1cc0050 >;  /* in zephyr\dts\arm\st\h7\stm32h7.dtsi:449 */
			interrupts = < 0x33 0x0 >;        /* in zephyr\dts\arm\st\h7\stm32h7.dtsi:451 */
			status = "disabled";              /* in zephyr\dts\arm\st\h7\stm32h7.dtsi:452 */
		};

		/* node '/soc/spi@40013400' defined in zephyr\dts\arm\st\h7\stm32h7.dtsi:455 */
		spi4: spi@40013400 {
			compatible = "st,stm32h7-spi",
			             "st,stm32-spi-fifo",
			             "st,stm32-spi";      /* in zephyr\dts\arm\st\h7\stm32h7.dtsi:456 */
			#address-cells = < 0x1 >;         /* in zephyr\dts\arm\st\h7\stm32h7.dtsi:457 */
			#size-cells = < 0x0 >;            /* in zephyr\dts\arm\st\h7\stm32h7.dtsi:458 */
			reg = < 0x40013400 0x400 >;       /* in zephyr\dts\arm\st\h7\stm32h7.dtsi:459 */
			clocks = < &rcc 0xf0 0x2000 >;    /* in zephyr\dts\arm\st\h7\stm32h7.dtsi:460 */
			interrupts = < 0x54 0x0 >;        /* in zephyr\dts\arm\st\h7\stm32h7.dtsi:461 */
			status = "disabled";              /* in zephyr\dts\arm\st\h7\stm32h7.dtsi:462 */
		};

		/* node '/soc/spi@40015000' defined in zephyr\dts\arm\st\h7\stm32h7.dtsi:465 */
		spi5: spi@40015000 {
			compatible = "st,stm32h7-spi",
			             "st,stm32-spi-fifo",
			             "st,stm32-spi";      /* in zephyr\dts\arm\st\h7\stm32h7.dtsi:466 */
			#address-cells = < 0x1 >;         /* in zephyr\dts\arm\st\h7\stm32h7.dtsi:467 */
			#size-cells = < 0x0 >;            /* in zephyr\dts\arm\st\h7\stm32h7.dtsi:468 */
			reg = < 0x40015000 0x400 >;       /* in zephyr\dts\arm\st\h7\stm32h7.dtsi:469 */
			clocks = < &rcc 0xf0 0x100000 >;  /* in zephyr\dts\arm\st\h7\stm32h7.dtsi:470 */
			interrupts = < 0x55 0x0 >;        /* in zephyr\dts\arm\st\h7\stm32h7.dtsi:471 */
			status = "disabled";              /* in zephyr\dts\arm\st\h7\stm32h7.dtsi:472 */
		};

		/* node '/soc/spi@58001400' defined in zephyr\dts\arm\st\h7\stm32h7.dtsi:475 */
		spi6: spi@58001400 {
			compatible = "st,stm32h7-spi",
			             "st,stm32-spi-fifo",
			             "st,stm32-spi";      /* in zephyr\dts\arm\st\h7\stm32h7.dtsi:476 */
			#address-cells = < 0x1 >;         /* in zephyr\dts\arm\st\h7\stm32h7.dtsi:477 */
			#size-cells = < 0x0 >;            /* in zephyr\dts\arm\st\h7\stm32h7.dtsi:478 */
			reg = < 0x58001400 0x400 >;       /* in zephyr\dts\arm\st\h7\stm32h7.dtsi:479 */
			clocks = < &rcc 0xf4 0x20 >;      /* in zephyr\dts\arm\st\h7\stm32h7.dtsi:480 */
			interrupts = < 0x56 0x0 >;        /* in zephyr\dts\arm\st\h7\stm32h7.dtsi:481 */
			status = "disabled";              /* in zephyr\dts\arm\st\h7\stm32h7.dtsi:482 */
		};

		/* node '/soc/i2s@40013000' defined in zephyr\dts\arm\st\h7\stm32h7.dtsi:485 */
		i2s1: i2s@40013000 {
			compatible = "st,stm32h7-i2s",
			             "st,stm32-i2s";                              /* in zephyr\dts\arm\st\h7\stm32h7.dtsi:486 */
			#address-cells = < 0x1 >;                                 /* in zephyr\dts\arm\st\h7\stm32h7.dtsi:487 */
			#size-cells = < 0x0 >;                                    /* in zephyr\dts\arm\st\h7\stm32h7.dtsi:488 */
			reg = < 0x40013000 0x400 >;                               /* in zephyr\dts\arm\st\h7\stm32h7.dtsi:489 */
			clocks = < &rcc 0xf0 0x1000 >,
			         < &rcc 0x9 0x1cc0050 >;                          /* in zephyr\dts\arm\st\h7\stm32h7.dtsi:490 */
			interrupts = < 0x23 0x3 >;                                /* in zephyr\dts\arm\st\h7\stm32h7.dtsi:495 */
			status = "okay";                                          /* in template_zephyr\boards\nucleo_h723zg.overlay:10 */
			pinctrl-0 = < &i2s1_ck_pa5 &i2s1_ws_pa4 &sai1_sd_a_pb2 >; /* in template_zephyr\boards\nucleo_h723zg.overlay:12 */
			pinctrl-names = "default";                                /* in template_zephyr\boards\nucleo_h723zg.overlay:13 */
			dmas = < &dmamux1 0x0 0x26 0x0 >,
			       < &dmamux1 0x1 0x25 0x0 >;                         /* in template_zephyr\boards\nucleo_h723zg.overlay:15 */
			dma-names = "tx",
			            "rx";                                         /* in template_zephyr\boards\nucleo_h723zg.overlay:17 */
		};

		/* node '/soc/i2s@40003800' defined in zephyr\dts\arm\st\h7\stm32h7.dtsi:499 */
		i2s2: i2s@40003800 {
			compatible = "st,stm32h7-i2s",
			             "st,stm32-i2s";                                    /* in zephyr\dts\arm\st\h7\stm32h7.dtsi:500 */
			#address-cells = < 0x1 >;                                       /* in zephyr\dts\arm\st\h7\stm32h7.dtsi:501 */
			#size-cells = < 0x0 >;                                          /* in zephyr\dts\arm\st\h7\stm32h7.dtsi:502 */
			reg = < 0x40003800 0x400 >;                                     /* in zephyr\dts\arm\st\h7\stm32h7.dtsi:503 */
			clocks = < &rcc 0xe8 0x4000 >,
			         < &rcc 0x9 0x1cc0050 >;                                /* in zephyr\dts\arm\st\h7\stm32h7.dtsi:504 */
			dmas = < &dmamux1 0x0 0x28 0x20440 &dmamux1 0x1 0x27 0x20480 >; /* in zephyr\dts\arm\st\h7\stm32h7.dtsi:506 */
			dma-names = "tx",
			            "rx";                                               /* in zephyr\dts\arm\st\h7\stm32h7.dtsi:508 */
			interrupts = < 0x24 0x0 >;                                      /* in zephyr\dts\arm\st\h7\stm32h7.dtsi:509 */
			status = "disabled";                                            /* in zephyr\dts\arm\st\h7\stm32h7.dtsi:510 */
		};

		/* node '/soc/i2s@40003c00' defined in zephyr\dts\arm\st\h7\stm32h7.dtsi:513 */
		i2s3: i2s@40003c00 {
			compatible = "st,stm32h7-i2s",
			             "st,stm32-i2s";                                    /* in zephyr\dts\arm\st\h7\stm32h7.dtsi:514 */
			#address-cells = < 0x1 >;                                       /* in zephyr\dts\arm\st\h7\stm32h7.dtsi:515 */
			#size-cells = < 0x0 >;                                          /* in zephyr\dts\arm\st\h7\stm32h7.dtsi:516 */
			reg = < 0x40003c00 0x400 >;                                     /* in zephyr\dts\arm\st\h7\stm32h7.dtsi:517 */
			clocks = < &rcc 0xe8 0x8000 >,
			         < &rcc 0x9 0x1cc0050 >;                                /* in zephyr\dts\arm\st\h7\stm32h7.dtsi:518 */
			dmas = < &dmamux1 0x0 0x3e 0x20440 &dmamux1 0x1 0x3d 0x20480 >; /* in zephyr\dts\arm\st\h7\stm32h7.dtsi:520 */
			dma-names = "tx",
			            "rx";                                               /* in zephyr\dts\arm\st\h7\stm32h7.dtsi:522 */
			interrupts = < 0x33 0x0 >;                                      /* in zephyr\dts\arm\st\h7\stm32h7.dtsi:523 */
			status = "disabled";                                            /* in zephyr\dts\arm\st\h7\stm32h7.dtsi:524 */
		};

		/* node '/soc/can@4000a000' defined in zephyr\dts\arm\st\h7\stm32h7.dtsi:527 */
		fdcan1: can@4000a000 {
			compatible = "st,stm32h7-fdcan";                       /* in zephyr\dts\arm\st\h7\stm32h7.dtsi:528 */
			reg = < 0x4000a000 0x400 >,
			      < 0x4000ac00 0x350 >;                            /* in zephyr\dts\arm\st\h7\stm32h7.dtsi:529 */
			reg-names = "m_can",
			            "message_ram";                             /* in zephyr\dts\arm\st\h7\stm32h7.dtsi:530 */
			interrupts = < 0x13 0x0 >,
			             < 0x15 0x0 >,
			             < 0x3f 0x0 >;                             /* in zephyr\dts\arm\st\h7\stm32h7.dtsi:532 */
			interrupt-names = "int0",
			                  "int1",
			                  "calib";                             /* in zephyr\dts\arm\st\h7\stm32h7.dtsi:533 */
			bosch,mram-cfg = < 0x0 0x1c 0x8 0x3 0x3 0x0 0x3 0x3 >; /* in zephyr\dts\arm\st\h7\stm32h7.dtsi:534 */
			pinctrl-0 = < &fdcan1_rx_pd0 &fdcan1_tx_pd1 >;         /* in zephyr\boards\st\nucleo_h723zg\nucleo_h723zg.dts:218 */
			pinctrl-names = "default";                             /* in zephyr\boards\st\nucleo_h723zg\nucleo_h723zg.dts:219 */
			clocks = < &rcc 0xec 0x100 >,
			         < &rcc 0xc 0x10dc0050 >;                      /* in zephyr\boards\st\nucleo_h723zg\nucleo_h723zg.dts:220 */
			status = "okay";                                       /* in zephyr\boards\st\nucleo_h723zg\nucleo_h723zg.dts:222 */
		};

		/* node '/soc/can@4000a400' defined in zephyr\dts\arm\st\h7\stm32h7.dtsi:538 */
		fdcan2: can@4000a400 {
			compatible = "st,stm32h7-fdcan";                         /* in zephyr\dts\arm\st\h7\stm32h7.dtsi:539 */
			reg = < 0x4000a400 0x400 >,
			      < 0x4000ac00 0x6a0 >;                              /* in zephyr\dts\arm\st\h7\stm32h7.dtsi:540 */
			reg-names = "m_can",
			            "message_ram";                               /* in zephyr\dts\arm\st\h7\stm32h7.dtsi:541 */
			clocks = < &rcc 0xec 0x100 >;                            /* in zephyr\dts\arm\st\h7\stm32h7.dtsi:542 */
			interrupts = < 0x14 0x0 >,
			             < 0x16 0x0 >,
			             < 0x3f 0x0 >;                               /* in zephyr\dts\arm\st\h7\stm32h7.dtsi:543 */
			interrupt-names = "int0",
			                  "int1",
			                  "calib";                               /* in zephyr\dts\arm\st\h7\stm32h7.dtsi:544 */
			bosch,mram-cfg = < 0x350 0x1c 0x8 0x3 0x3 0x0 0x3 0x3 >; /* in zephyr\dts\arm\st\h7\stm32h7.dtsi:545 */
			status = "disabled";                                     /* in zephyr\dts\arm\st\h7\stm32h7.dtsi:546 */
		};

		/* node '/soc/timers@40010000' defined in zephyr\dts\arm\st\h7\stm32h7.dtsi:549 */
		timers1: timers@40010000 {
			compatible = "st,stm32-timers"; /* in zephyr\dts\arm\st\h7\stm32h7.dtsi:550 */
			reg = < 0x40010000 0x400 >;     /* in zephyr\dts\arm\st\h7\stm32h7.dtsi:551 */
			clocks = < &rcc 0xf0 0x1 >;     /* in zephyr\dts\arm\st\h7\stm32h7.dtsi:552 */
			resets = < &rctl 0x1300 >;      /* in zephyr\dts\arm\st\h7\stm32h7.dtsi:553 */
			interrupts = < 0x18 0x0 >,
			             < 0x19 0x0 >,
			             < 0x1a 0x0 >,
			             < 0x1b 0x0 >;      /* in zephyr\dts\arm\st\h7\stm32h7.dtsi:554 */
			interrupt-names = "brk",
			                  "up",
			                  "trgcom",
			                  "cc";         /* in zephyr\dts\arm\st\h7\stm32h7.dtsi:555 */
			st,prescaler = < 0x0 >;         /* in zephyr\dts\arm\st\h7\stm32h7.dtsi:556 */
			status = "disabled";            /* in zephyr\dts\arm\st\h7\stm32h7.dtsi:557 */

			/* node '/soc/timers@40010000/pwm' defined in zephyr\dts\arm\st\h7\stm32h7.dtsi:559 */
			pwm {
				compatible = "st,stm32-pwm"; /* in zephyr\dts\arm\st\h7\stm32h7.dtsi:560 */
				status = "disabled";         /* in zephyr\dts\arm\st\h7\stm32h7.dtsi:561 */
				#pwm-cells = < 0x3 >;        /* in zephyr\dts\arm\st\h7\stm32h7.dtsi:562 */
			};
		};

		/* node '/soc/timers@40000000' defined in zephyr\dts\arm\st\h7\stm32h7.dtsi:566 */
		timers2: timers@40000000 {
			compatible = "st,stm32-timers"; /* in zephyr\dts\arm\st\h7\stm32h7.dtsi:567 */
			reg = < 0x40000000 0x400 >;     /* in zephyr\dts\arm\st\h7\stm32h7.dtsi:568 */
			clocks = < &rcc 0xe8 0x1 >;     /* in zephyr\dts\arm\st\h7\stm32h7.dtsi:569 */
			resets = < &rctl 0x1200 >;      /* in zephyr\dts\arm\st\h7\stm32h7.dtsi:570 */
			interrupts = < 0x1c 0x0 >;      /* in zephyr\dts\arm\st\h7\stm32h7.dtsi:571 */
			interrupt-names = "global";     /* in zephyr\dts\arm\st\h7\stm32h7.dtsi:572 */
			st,prescaler = < 0x0 >;         /* in zephyr\dts\arm\st\h7\stm32h7.dtsi:573 */
			status = "disabled";            /* in zephyr\dts\arm\st\h7\stm32h7.dtsi:574 */

			/* node '/soc/timers@40000000/pwm' defined in zephyr\dts\arm\st\h7\stm32h7.dtsi:576 */
			pwm {
				compatible = "st,stm32-pwm"; /* in zephyr\dts\arm\st\h7\stm32h7.dtsi:577 */
				status = "disabled";         /* in zephyr\dts\arm\st\h7\stm32h7.dtsi:578 */
				#pwm-cells = < 0x3 >;        /* in zephyr\dts\arm\st\h7\stm32h7.dtsi:579 */
			};

			/* node '/soc/timers@40000000/counter' defined in zephyr\dts\arm\st\h7\stm32h7.dtsi:582 */
			counter {
				compatible = "st,stm32-counter"; /* in zephyr\dts\arm\st\h7\stm32h7.dtsi:583 */
				status = "disabled";             /* in zephyr\dts\arm\st\h7\stm32h7.dtsi:584 */
			};
		};

		/* node '/soc/timers@40000400' defined in zephyr\dts\arm\st\h7\stm32h7.dtsi:588 */
		timers3: timers@40000400 {
			compatible = "st,stm32-timers"; /* in zephyr\dts\arm\st\h7\stm32h7.dtsi:589 */
			reg = < 0x40000400 0x400 >;     /* in zephyr\dts\arm\st\h7\stm32h7.dtsi:590 */
			clocks = < &rcc 0xe8 0x2 >;     /* in zephyr\dts\arm\st\h7\stm32h7.dtsi:591 */
			resets = < &rctl 0x1201 >;      /* in zephyr\dts\arm\st\h7\stm32h7.dtsi:592 */
			interrupts = < 0x1d 0x0 >;      /* in zephyr\dts\arm\st\h7\stm32h7.dtsi:593 */
			interrupt-names = "global";     /* in zephyr\dts\arm\st\h7\stm32h7.dtsi:594 */
			st,prescaler = < 0x0 >;         /* in zephyr\dts\arm\st\h7\stm32h7.dtsi:595 */
			status = "disabled";            /* in zephyr\dts\arm\st\h7\stm32h7.dtsi:596 */

			/* node '/soc/timers@40000400/pwm' defined in zephyr\dts\arm\st\h7\stm32h7.dtsi:598 */
			pwm {
				compatible = "st,stm32-pwm"; /* in zephyr\dts\arm\st\h7\stm32h7.dtsi:599 */
				status = "disabled";         /* in zephyr\dts\arm\st\h7\stm32h7.dtsi:600 */
				#pwm-cells = < 0x3 >;        /* in zephyr\dts\arm\st\h7\stm32h7.dtsi:601 */
			};

			/* node '/soc/timers@40000400/counter' defined in zephyr\dts\arm\st\h7\stm32h7.dtsi:604 */
			counter {
				compatible = "st,stm32-counter"; /* in zephyr\dts\arm\st\h7\stm32h7.dtsi:605 */
				status = "disabled";             /* in zephyr\dts\arm\st\h7\stm32h7.dtsi:606 */
			};
		};

		/* node '/soc/timers@40000800' defined in zephyr\dts\arm\st\h7\stm32h7.dtsi:610 */
		timers4: timers@40000800 {
			compatible = "st,stm32-timers"; /* in zephyr\dts\arm\st\h7\stm32h7.dtsi:611 */
			reg = < 0x40000800 0x400 >;     /* in zephyr\dts\arm\st\h7\stm32h7.dtsi:612 */
			clocks = < &rcc 0xe8 0x4 >;     /* in zephyr\dts\arm\st\h7\stm32h7.dtsi:613 */
			resets = < &rctl 0x1202 >;      /* in zephyr\dts\arm\st\h7\stm32h7.dtsi:614 */
			interrupts = < 0x1e 0x0 >;      /* in zephyr\dts\arm\st\h7\stm32h7.dtsi:615 */
			interrupt-names = "global";     /* in zephyr\dts\arm\st\h7\stm32h7.dtsi:616 */
			st,prescaler = < 0x0 >;         /* in zephyr\dts\arm\st\h7\stm32h7.dtsi:617 */
			status = "disabled";            /* in zephyr\dts\arm\st\h7\stm32h7.dtsi:618 */

			/* node '/soc/timers@40000800/pwm' defined in zephyr\dts\arm\st\h7\stm32h7.dtsi:620 */
			pwm {
				compatible = "st,stm32-pwm"; /* in zephyr\dts\arm\st\h7\stm32h7.dtsi:621 */
				status = "disabled";         /* in zephyr\dts\arm\st\h7\stm32h7.dtsi:622 */
				#pwm-cells = < 0x3 >;        /* in zephyr\dts\arm\st\h7\stm32h7.dtsi:623 */
			};

			/* node '/soc/timers@40000800/counter' defined in zephyr\dts\arm\st\h7\stm32h7.dtsi:626 */
			counter {
				compatible = "st,stm32-counter"; /* in zephyr\dts\arm\st\h7\stm32h7.dtsi:627 */
				status = "disabled";             /* in zephyr\dts\arm\st\h7\stm32h7.dtsi:628 */
			};
		};

		/* node '/soc/timers@40000c00' defined in zephyr\dts\arm\st\h7\stm32h7.dtsi:632 */
		timers5: timers@40000c00 {
			compatible = "st,stm32-timers"; /* in zephyr\dts\arm\st\h7\stm32h7.dtsi:633 */
			reg = < 0x40000c00 0x400 >;     /* in zephyr\dts\arm\st\h7\stm32h7.dtsi:634 */
			clocks = < &rcc 0xe8 0x8 >;     /* in zephyr\dts\arm\st\h7\stm32h7.dtsi:635 */
			resets = < &rctl 0x1203 >;      /* in zephyr\dts\arm\st\h7\stm32h7.dtsi:636 */
			interrupts = < 0x32 0x0 >;      /* in zephyr\dts\arm\st\h7\stm32h7.dtsi:637 */
			interrupt-names = "global";     /* in zephyr\dts\arm\st\h7\stm32h7.dtsi:638 */
			st,prescaler = < 0x0 >;         /* in zephyr\dts\arm\st\h7\stm32h7.dtsi:639 */
			status = "disabled";            /* in zephyr\dts\arm\st\h7\stm32h7.dtsi:640 */

			/* node '/soc/timers@40000c00/pwm' defined in zephyr\dts\arm\st\h7\stm32h7.dtsi:642 */
			pwm {
				compatible = "st,stm32-pwm"; /* in zephyr\dts\arm\st\h7\stm32h7.dtsi:643 */
				status = "disabled";         /* in zephyr\dts\arm\st\h7\stm32h7.dtsi:644 */
				#pwm-cells = < 0x3 >;        /* in zephyr\dts\arm\st\h7\stm32h7.dtsi:645 */
			};

			/* node '/soc/timers@40000c00/counter' defined in zephyr\dts\arm\st\h7\stm32h7.dtsi:648 */
			counter {
				compatible = "st,stm32-counter"; /* in zephyr\dts\arm\st\h7\stm32h7.dtsi:649 */
				status = "disabled";             /* in zephyr\dts\arm\st\h7\stm32h7.dtsi:650 */
			};
		};

		/* node '/soc/timers@40001000' defined in zephyr\dts\arm\st\h7\stm32h7.dtsi:654 */
		timers6: timers@40001000 {
			compatible = "st,stm32-timers"; /* in zephyr\dts\arm\st\h7\stm32h7.dtsi:655 */
			reg = < 0x40001000 0x400 >;     /* in zephyr\dts\arm\st\h7\stm32h7.dtsi:656 */
			clocks = < &rcc 0xe8 0x10 >;    /* in zephyr\dts\arm\st\h7\stm32h7.dtsi:657 */
			resets = < &rctl 0x1204 >;      /* in zephyr\dts\arm\st\h7\stm32h7.dtsi:658 */
			interrupts = < 0x36 0x0 >;      /* in zephyr\dts\arm\st\h7\stm32h7.dtsi:659 */
			interrupt-names = "global";     /* in zephyr\dts\arm\st\h7\stm32h7.dtsi:660 */
			st,prescaler = < 0x0 >;         /* in zephyr\dts\arm\st\h7\stm32h7.dtsi:661 */
			status = "disabled";            /* in zephyr\dts\arm\st\h7\stm32h7.dtsi:662 */

			/* node '/soc/timers@40001000/counter' defined in zephyr\dts\arm\st\h7\stm32h7.dtsi:664 */
			counter {
				compatible = "st,stm32-counter"; /* in zephyr\dts\arm\st\h7\stm32h7.dtsi:665 */
				status = "disabled";             /* in zephyr\dts\arm\st\h7\stm32h7.dtsi:666 */
			};
		};

		/* node '/soc/timers@40001400' defined in zephyr\dts\arm\st\h7\stm32h7.dtsi:670 */
		timers7: timers@40001400 {
			compatible = "st,stm32-timers"; /* in zephyr\dts\arm\st\h7\stm32h7.dtsi:671 */
			reg = < 0x40001400 0x400 >;     /* in zephyr\dts\arm\st\h7\stm32h7.dtsi:672 */
			clocks = < &rcc 0xe8 0x20 >;    /* in zephyr\dts\arm\st\h7\stm32h7.dtsi:673 */
			resets = < &rctl 0x1205 >;      /* in zephyr\dts\arm\st\h7\stm32h7.dtsi:674 */
			interrupts = < 0x37 0x0 >;      /* in zephyr\dts\arm\st\h7\stm32h7.dtsi:675 */
			interrupt-names = "global";     /* in zephyr\dts\arm\st\h7\stm32h7.dtsi:676 */
			st,prescaler = < 0x0 >;         /* in zephyr\dts\arm\st\h7\stm32h7.dtsi:677 */
			status = "disabled";            /* in zephyr\dts\arm\st\h7\stm32h7.dtsi:678 */

			/* node '/soc/timers@40001400/counter' defined in zephyr\dts\arm\st\h7\stm32h7.dtsi:680 */
			counter {
				compatible = "st,stm32-counter"; /* in zephyr\dts\arm\st\h7\stm32h7.dtsi:681 */
				status = "disabled";             /* in zephyr\dts\arm\st\h7\stm32h7.dtsi:682 */
			};
		};

		/* node '/soc/timers@40010400' defined in zephyr\dts\arm\st\h7\stm32h7.dtsi:686 */
		timers8: timers@40010400 {
			compatible = "st,stm32-timers"; /* in zephyr\dts\arm\st\h7\stm32h7.dtsi:687 */
			reg = < 0x40010400 0x400 >;     /* in zephyr\dts\arm\st\h7\stm32h7.dtsi:688 */
			clocks = < &rcc 0xf0 0x2 >;     /* in zephyr\dts\arm\st\h7\stm32h7.dtsi:689 */
			resets = < &rctl 0x1301 >;      /* in zephyr\dts\arm\st\h7\stm32h7.dtsi:690 */
			interrupts = < 0x2b 0x0 >,
			             < 0x2c 0x0 >,
			             < 0x2d 0x0 >,
			             < 0x2e 0x0 >;      /* in zephyr\dts\arm\st\h7\stm32h7.dtsi:691 */
			interrupt-names = "brk",
			                  "up",
			                  "trgcom",
			                  "cc";         /* in zephyr\dts\arm\st\h7\stm32h7.dtsi:692 */
			st,prescaler = < 0x0 >;         /* in zephyr\dts\arm\st\h7\stm32h7.dtsi:693 */
			status = "disabled";            /* in zephyr\dts\arm\st\h7\stm32h7.dtsi:694 */

			/* node '/soc/timers@40010400/pwm' defined in zephyr\dts\arm\st\h7\stm32h7.dtsi:696 */
			pwm {
				compatible = "st,stm32-pwm"; /* in zephyr\dts\arm\st\h7\stm32h7.dtsi:697 */
				status = "disabled";         /* in zephyr\dts\arm\st\h7\stm32h7.dtsi:698 */
				#pwm-cells = < 0x3 >;        /* in zephyr\dts\arm\st\h7\stm32h7.dtsi:699 */
			};
		};

		/* node '/soc/timers@40001800' defined in zephyr\dts\arm\st\h7\stm32h7.dtsi:703 */
		timers12: timers@40001800 {
			compatible = "st,stm32-timers"; /* in zephyr\dts\arm\st\h7\stm32h7.dtsi:704 */
			reg = < 0x40001800 0x400 >;     /* in zephyr\dts\arm\st\h7\stm32h7.dtsi:705 */
			clocks = < &rcc 0xe8 0x40 >;    /* in zephyr\dts\arm\st\h7\stm32h7.dtsi:706 */
			resets = < &rctl 0x1206 >;      /* in zephyr\dts\arm\st\h7\stm32h7.dtsi:707 */
			interrupts = < 0x2b 0x0 >;      /* in zephyr\dts\arm\st\h7\stm32h7.dtsi:708 */
			interrupt-names = "global";     /* in zephyr\dts\arm\st\h7\stm32h7.dtsi:709 */
			st,prescaler = < 0x2710 >;      /* in zephyr\boards\st\nucleo_h723zg\nucleo_h723zg.dts:172 */
			status = "okay";                /* in zephyr\boards\st\nucleo_h723zg\nucleo_h723zg.dts:173 */

			/* node '/soc/timers@40001800/pwm' defined in zephyr\dts\arm\st\h7\stm32h7.dtsi:713 */
			pwm12: pwm {
				compatible = "st,stm32-pwm";     /* in zephyr\dts\arm\st\h7\stm32h7.dtsi:714 */
				#pwm-cells = < 0x3 >;            /* in zephyr\dts\arm\st\h7\stm32h7.dtsi:716 */
				status = "okay";                 /* in zephyr\boards\st\nucleo_h723zg\nucleo_h723zg.dts:176 */
				pinctrl-0 = < &tim12_ch1_pb14 >; /* in zephyr\boards\st\nucleo_h723zg\nucleo_h723zg.dts:177 */
				pinctrl-names = "default";       /* in zephyr\boards\st\nucleo_h723zg\nucleo_h723zg.dts:178 */
				phandle = < 0x32 >;              /* in zephyr\boards\st\nucleo_h723zg\nucleo_h723zg.dts:53 */
			};

			/* node '/soc/timers@40001800/counter' defined in zephyr\dts\arm\st\h7\stm32h7.dtsi:719 */
			counter {
				compatible = "st,stm32-counter"; /* in zephyr\dts\arm\st\h7\stm32h7.dtsi:720 */
				status = "disabled";             /* in zephyr\dts\arm\st\h7\stm32h7.dtsi:721 */
			};
		};

		/* node '/soc/timers@40001c00' defined in zephyr\dts\arm\st\h7\stm32h7.dtsi:725 */
		timers13: timers@40001c00 {
			compatible = "st,stm32-timers"; /* in zephyr\dts\arm\st\h7\stm32h7.dtsi:726 */
			reg = < 0x40001c00 0x400 >;     /* in zephyr\dts\arm\st\h7\stm32h7.dtsi:727 */
			clocks = < &rcc 0xe8 0x80 >;    /* in zephyr\dts\arm\st\h7\stm32h7.dtsi:728 */
			resets = < &rctl 0x1207 >;      /* in zephyr\dts\arm\st\h7\stm32h7.dtsi:729 */
			interrupts = < 0x2c 0x0 >;      /* in zephyr\dts\arm\st\h7\stm32h7.dtsi:730 */
			interrupt-names = "global";     /* in zephyr\dts\arm\st\h7\stm32h7.dtsi:731 */
			st,prescaler = < 0x0 >;         /* in zephyr\dts\arm\st\h7\stm32h7.dtsi:732 */
			status = "disabled";            /* in zephyr\dts\arm\st\h7\stm32h7.dtsi:733 */

			/* node '/soc/timers@40001c00/pwm' defined in zephyr\dts\arm\st\h7\stm32h7.dtsi:735 */
			pwm {
				compatible = "st,stm32-pwm"; /* in zephyr\dts\arm\st\h7\stm32h7.dtsi:736 */
				status = "disabled";         /* in zephyr\dts\arm\st\h7\stm32h7.dtsi:737 */
				#pwm-cells = < 0x3 >;        /* in zephyr\dts\arm\st\h7\stm32h7.dtsi:738 */
			};

			/* node '/soc/timers@40001c00/counter' defined in zephyr\dts\arm\st\h7\stm32h7.dtsi:741 */
			counter {
				compatible = "st,stm32-counter"; /* in zephyr\dts\arm\st\h7\stm32h7.dtsi:742 */
				status = "disabled";             /* in zephyr\dts\arm\st\h7\stm32h7.dtsi:743 */
			};
		};

		/* node '/soc/timers@40002000' defined in zephyr\dts\arm\st\h7\stm32h7.dtsi:747 */
		timers14: timers@40002000 {
			compatible = "st,stm32-timers"; /* in zephyr\dts\arm\st\h7\stm32h7.dtsi:748 */
			reg = < 0x40002000 0x400 >;     /* in zephyr\dts\arm\st\h7\stm32h7.dtsi:749 */
			clocks = < &rcc 0xe8 0x100 >;   /* in zephyr\dts\arm\st\h7\stm32h7.dtsi:750 */
			resets = < &rctl 0x1208 >;      /* in zephyr\dts\arm\st\h7\stm32h7.dtsi:751 */
			interrupts = < 0x2d 0x0 >;      /* in zephyr\dts\arm\st\h7\stm32h7.dtsi:752 */
			interrupt-names = "global";     /* in zephyr\dts\arm\st\h7\stm32h7.dtsi:753 */
			st,prescaler = < 0x0 >;         /* in zephyr\dts\arm\st\h7\stm32h7.dtsi:754 */
			status = "disabled";            /* in zephyr\dts\arm\st\h7\stm32h7.dtsi:755 */

			/* node '/soc/timers@40002000/pwm' defined in zephyr\dts\arm\st\h7\stm32h7.dtsi:757 */
			pwm {
				compatible = "st,stm32-pwm"; /* in zephyr\dts\arm\st\h7\stm32h7.dtsi:758 */
				status = "disabled";         /* in zephyr\dts\arm\st\h7\stm32h7.dtsi:759 */
				#pwm-cells = < 0x3 >;        /* in zephyr\dts\arm\st\h7\stm32h7.dtsi:760 */
			};

			/* node '/soc/timers@40002000/counter' defined in zephyr\dts\arm\st\h7\stm32h7.dtsi:763 */
			counter {
				compatible = "st,stm32-counter"; /* in zephyr\dts\arm\st\h7\stm32h7.dtsi:764 */
				status = "disabled";             /* in zephyr\dts\arm\st\h7\stm32h7.dtsi:765 */
			};
		};

		/* node '/soc/timers@40014000' defined in zephyr\dts\arm\st\h7\stm32h7.dtsi:769 */
		timers15: timers@40014000 {
			compatible = "st,stm32-timers"; /* in zephyr\dts\arm\st\h7\stm32h7.dtsi:770 */
			reg = < 0x40014000 0x400 >;     /* in zephyr\dts\arm\st\h7\stm32h7.dtsi:771 */
			clocks = < &rcc 0xf0 0x10000 >; /* in zephyr\dts\arm\st\h7\stm32h7.dtsi:772 */
			resets = < &rctl 0x1310 >;      /* in zephyr\dts\arm\st\h7\stm32h7.dtsi:773 */
			interrupts = < 0x74 0x0 >;      /* in zephyr\dts\arm\st\h7\stm32h7.dtsi:774 */
			interrupt-names = "global";     /* in zephyr\dts\arm\st\h7\stm32h7.dtsi:775 */
			st,prescaler = < 0x0 >;         /* in zephyr\dts\arm\st\h7\stm32h7.dtsi:776 */
			status = "disabled";            /* in zephyr\dts\arm\st\h7\stm32h7.dtsi:777 */

			/* node '/soc/timers@40014000/pwm' defined in zephyr\dts\arm\st\h7\stm32h7.dtsi:779 */
			pwm {
				compatible = "st,stm32-pwm"; /* in zephyr\dts\arm\st\h7\stm32h7.dtsi:780 */
				status = "disabled";         /* in zephyr\dts\arm\st\h7\stm32h7.dtsi:781 */
				#pwm-cells = < 0x3 >;        /* in zephyr\dts\arm\st\h7\stm32h7.dtsi:782 */
			};

			/* node '/soc/timers@40014000/counter' defined in zephyr\dts\arm\st\h7\stm32h7.dtsi:785 */
			counter {
				compatible = "st,stm32-counter"; /* in zephyr\dts\arm\st\h7\stm32h7.dtsi:786 */
				status = "disabled";             /* in zephyr\dts\arm\st\h7\stm32h7.dtsi:787 */
			};
		};

		/* node '/soc/timers@40014400' defined in zephyr\dts\arm\st\h7\stm32h7.dtsi:791 */
		timers16: timers@40014400 {
			compatible = "st,stm32-timers"; /* in zephyr\dts\arm\st\h7\stm32h7.dtsi:792 */
			reg = < 0x40014400 0x400 >;     /* in zephyr\dts\arm\st\h7\stm32h7.dtsi:793 */
			clocks = < &rcc 0xf0 0x20000 >; /* in zephyr\dts\arm\st\h7\stm32h7.dtsi:794 */
			resets = < &rctl 0x1311 >;      /* in zephyr\dts\arm\st\h7\stm32h7.dtsi:795 */
			interrupts = < 0x75 0x0 >;      /* in zephyr\dts\arm\st\h7\stm32h7.dtsi:796 */
			interrupt-names = "global";     /* in zephyr\dts\arm\st\h7\stm32h7.dtsi:797 */
			st,prescaler = < 0x0 >;         /* in zephyr\dts\arm\st\h7\stm32h7.dtsi:798 */
			status = "disabled";            /* in zephyr\dts\arm\st\h7\stm32h7.dtsi:799 */

			/* node '/soc/timers@40014400/pwm' defined in zephyr\dts\arm\st\h7\stm32h7.dtsi:801 */
			pwm {
				compatible = "st,stm32-pwm"; /* in zephyr\dts\arm\st\h7\stm32h7.dtsi:802 */
				status = "disabled";         /* in zephyr\dts\arm\st\h7\stm32h7.dtsi:803 */
				#pwm-cells = < 0x3 >;        /* in zephyr\dts\arm\st\h7\stm32h7.dtsi:804 */
			};

			/* node '/soc/timers@40014400/counter' defined in zephyr\dts\arm\st\h7\stm32h7.dtsi:807 */
			counter {
				compatible = "st,stm32-counter"; /* in zephyr\dts\arm\st\h7\stm32h7.dtsi:808 */
				status = "disabled";             /* in zephyr\dts\arm\st\h7\stm32h7.dtsi:809 */
			};
		};

		/* node '/soc/timers@40014800' defined in zephyr\dts\arm\st\h7\stm32h7.dtsi:813 */
		timers17: timers@40014800 {
			compatible = "st,stm32-timers"; /* in zephyr\dts\arm\st\h7\stm32h7.dtsi:814 */
			reg = < 0x40014800 0x400 >;     /* in zephyr\dts\arm\st\h7\stm32h7.dtsi:815 */
			clocks = < &rcc 0xf0 0x40000 >; /* in zephyr\dts\arm\st\h7\stm32h7.dtsi:816 */
			resets = < &rctl 0x1312 >;      /* in zephyr\dts\arm\st\h7\stm32h7.dtsi:817 */
			interrupts = < 0x76 0x0 >;      /* in zephyr\dts\arm\st\h7\stm32h7.dtsi:818 */
			interrupt-names = "global";     /* in zephyr\dts\arm\st\h7\stm32h7.dtsi:819 */
			st,prescaler = < 0x0 >;         /* in zephyr\dts\arm\st\h7\stm32h7.dtsi:820 */
			status = "disabled";            /* in zephyr\dts\arm\st\h7\stm32h7.dtsi:821 */

			/* node '/soc/timers@40014800/pwm' defined in zephyr\dts\arm\st\h7\stm32h7.dtsi:823 */
			pwm {
				compatible = "st,stm32-pwm"; /* in zephyr\dts\arm\st\h7\stm32h7.dtsi:824 */
				status = "disabled";         /* in zephyr\dts\arm\st\h7\stm32h7.dtsi:825 */
				#pwm-cells = < 0x3 >;        /* in zephyr\dts\arm\st\h7\stm32h7.dtsi:826 */
			};

			/* node '/soc/timers@40014800/counter' defined in zephyr\dts\arm\st\h7\stm32h7.dtsi:829 */
			counter {
				compatible = "st,stm32-counter"; /* in zephyr\dts\arm\st\h7\stm32h7.dtsi:830 */
				status = "disabled";             /* in zephyr\dts\arm\st\h7\stm32h7.dtsi:831 */
			};
		};

		/* node '/soc/timers@40002400' defined in zephyr\dts\arm\st\h7\stm32h7.dtsi:835 */
		lptim1: timers@40002400 {
			compatible = "st,stm32-lptim"; /* in zephyr\dts\arm\st\h7\stm32h7.dtsi:836 */
			clocks = < &rcc 0xe8 0x200 >;  /* in zephyr\dts\arm\st\h7\stm32h7.dtsi:837 */
			#address-cells = < 0x1 >;      /* in zephyr\dts\arm\st\h7\stm32h7.dtsi:838 */
			#size-cells = < 0x0 >;         /* in zephyr\dts\arm\st\h7\stm32h7.dtsi:839 */
			reg = < 0x40002400 0x400 >;    /* in zephyr\dts\arm\st\h7\stm32h7.dtsi:840 */
			interrupts = < 0x5d 0x1 >;     /* in zephyr\dts\arm\st\h7\stm32h7.dtsi:841 */
			interrupt-names = "wakeup";    /* in zephyr\dts\arm\st\h7\stm32h7.dtsi:842 */
			status = "disabled";           /* in zephyr\dts\arm\st\h7\stm32h7.dtsi:843 */
		};

		/* node '/soc/adc@40022000' defined in zephyr\dts\arm\st\h7\stm32h7.dtsi:853 */
		adc1: adc@40022000 {
			compatible = "st,stm32-adc";                                    /* in zephyr\dts\arm\st\h7\stm32h7.dtsi:854 */
			reg = < 0x40022000 0x400 >;                                     /* in zephyr\dts\arm\st\h7\stm32h7.dtsi:855 */
			clocks = < &rcc 0xd8 0x20 >;                                    /* in zephyr\dts\arm\st\h7\stm32h7.dtsi:856 */
			interrupts = < 0x12 0x0 >;                                      /* in zephyr\dts\arm\st\h7\stm32h7.dtsi:857 */
			status = "disabled";                                            /* in zephyr\dts\arm\st\h7\stm32h7.dtsi:858 */
			#io-channel-cells = < 0x1 >;                                    /* in zephyr\dts\arm\st\h7\stm32h7.dtsi:859 */
			resolutions = < 0x80e20c 0x75e20c 0x66e20c 0x53e20c 0x47e20c >; /* in zephyr\dts\arm\st\h7\stm32h7.dtsi:860 */
			sampling-times = < 0x2 0x3 0x9 0x11 0x21 0x41 0x184 0x32b >;    /* in zephyr\dts\arm\st\h7\stm32h7.dtsi:865 */
			st,adc-sequencer = "FULLY_CONFIGURABLE";                        /* in zephyr\dts\arm\st\h7\stm32h7.dtsi:866 */
			st,adc-oversampler = "OVERSAMPLER_EXTENDED";                    /* in zephyr\dts\arm\st\h7\stm32h7.dtsi:867 */
		};

		/* node '/soc/adc@40022100' defined in zephyr\dts\arm\st\h7\stm32h7.dtsi:870 */
		adc2: adc@40022100 {
			compatible = "st,stm32-adc";                                    /* in zephyr\dts\arm\st\h7\stm32h7.dtsi:871 */
			reg = < 0x40022100 0x400 >;                                     /* in zephyr\dts\arm\st\h7\stm32h7.dtsi:872 */
			clocks = < &rcc 0xd8 0x20 >;                                    /* in zephyr\dts\arm\st\h7\stm32h7.dtsi:873 */
			interrupts = < 0x12 0x0 >;                                      /* in zephyr\dts\arm\st\h7\stm32h7.dtsi:874 */
			status = "disabled";                                            /* in zephyr\dts\arm\st\h7\stm32h7.dtsi:875 */
			#io-channel-cells = < 0x1 >;                                    /* in zephyr\dts\arm\st\h7\stm32h7.dtsi:876 */
			resolutions = < 0x80e20c 0x75e20c 0x66e20c 0x53e20c 0x47e20c >; /* in zephyr\dts\arm\st\h7\stm32h7.dtsi:877 */
			sampling-times = < 0x2 0x3 0x9 0x11 0x21 0x41 0x184 0x32b >;    /* in zephyr\dts\arm\st\h7\stm32h7.dtsi:882 */
			st,adc-sequencer = "FULLY_CONFIGURABLE";                        /* in zephyr\dts\arm\st\h7\stm32h7.dtsi:883 */
			st,adc-oversampler = "OVERSAMPLER_EXTENDED";                    /* in zephyr\dts\arm\st\h7\stm32h7.dtsi:884 */
		};

		/* node '/soc/adc@40022300' defined in zephyr\dts\arm\st\h7\stm32h7.dtsi:888 */
		adc1_2: adc@40022300 {
			compatible = "st,stm32-adc";                                    /* in zephyr\dts\arm\st\h7\stm32h7.dtsi:889 */
			reg = < 0x40022300 0x400 >;                                     /* in zephyr\dts\arm\st\h7\stm32h7.dtsi:890 */
			clocks = < &rcc 0xd8 0x20 >;                                    /* in zephyr\dts\arm\st\h7\stm32h7.dtsi:891 */
			interrupts = < 0x12 0x0 >;                                      /* in zephyr\dts\arm\st\h7\stm32h7.dtsi:892 */
			status = "disabled";                                            /* in zephyr\dts\arm\st\h7\stm32h7.dtsi:893 */
			#io-channel-cells = < 0x1 >;                                    /* in zephyr\dts\arm\st\h7\stm32h7.dtsi:894 */
			resolutions = < 0x80e20c 0x75e20c 0x66e20c 0x53e20c 0x47e20c >; /* in zephyr\dts\arm\st\h7\stm32h7.dtsi:895 */
			sampling-times = < 0x2 0x3 0x9 0x11 0x21 0x41 0x184 0x32b >;    /* in zephyr\dts\arm\st\h7\stm32h7.dtsi:900 */
			st,adc-sequencer = "FULLY_CONFIGURABLE";                        /* in zephyr\dts\arm\st\h7\stm32h7.dtsi:901 */
			st,adc-oversampler = "OVERSAMPLER_EXTENDED";                    /* in zephyr\dts\arm\st\h7\stm32h7.dtsi:902 */
		};

		/* node '/soc/adc@58026000' defined in zephyr\dts\arm\st\h7\stm32h7.dtsi:905 */
		adc3: adc@58026000 {
			compatible = "st,stm32-adc";                                /* in zephyr\dts\arm\st\h7\stm32h7.dtsi:906 */
			reg = < 0x58026000 0x400 >;                                 /* in zephyr\dts\arm\st\h7\stm32h7.dtsi:907 */
			clocks = < &rcc 0xe0 0x1000000 >;                           /* in zephyr\dts\arm\st\h7\stm32h7.dtsi:908 */
			interrupts = < 0x7f 0x0 >;                                  /* in zephyr\dts\arm\st\h7\stm32h7.dtsi:909 */
			status = "disabled";                                        /* in zephyr\dts\arm\st\h7\stm32h7.dtsi:910 */
			#io-channel-cells = < 0x1 >;                                /* in zephyr\dts\arm\st\h7\stm32h7.dtsi:911 */
			resolutions = < 0x60630c 0x51630c 0x42630c 0x33630c >;      /* in zephyr\dts\arm\st\h7\stm32h723.dtsi:50 */
			sampling-times = < 0x3 0x7 0xd 0x19 0x30 0x5d 0xf8 0x281 >; /* in zephyr\dts\arm\st\h7\stm32h723.dtsi:54 */
			st,adc-sequencer = "FULLY_CONFIGURABLE";                    /* in zephyr\dts\arm\st\h7\stm32h723.dtsi:55 */
			st,adc-oversampler = "OVERSAMPLER_MINIMAL";                 /* in zephyr\dts\arm\st\h7\stm32h723.dtsi:56 */
			phandle = < 0x27 >;                                         /* in zephyr\dts\arm\st\h7\stm32h723.dtsi:240 */
		};

		/* node '/soc/dac@40007400' defined in zephyr\dts\arm\st\h7\stm32h7.dtsi:922 */
		dac1: dac@40007400 {
			compatible = "st,stm32-dac";       /* in zephyr\dts\arm\st\h7\stm32h7.dtsi:923 */
			reg = < 0x40007400 0x400 >;        /* in zephyr\dts\arm\st\h7\stm32h7.dtsi:924 */
			clocks = < &rcc 0xe8 0x20000000 >; /* in zephyr\dts\arm\st\h7\stm32h7.dtsi:925 */
			status = "disabled";               /* in zephyr\dts\arm\st\h7\stm32h7.dtsi:926 */
			#io-channel-cells = < 0x1 >;       /* in zephyr\dts\arm\st\h7\stm32h7.dtsi:927 */
		};

		/* node '/soc/dma@40020000' defined in zephyr\dts\arm\st\h7\stm32h7.dtsi:930 */
		dma1: dma@40020000 {
			compatible = "st,stm32-dma-v1"; /* in zephyr\dts\arm\st\h7\stm32h7.dtsi:931 */
			#dma-cells = < 0x4 >;           /* in zephyr\dts\arm\st\h7\stm32h7.dtsi:932 */
			reg = < 0x40020000 0x400 >;     /* in zephyr\dts\arm\st\h7\stm32h7.dtsi:933 */
			interrupts = < 0xb 0x0 >,
			             < 0xc 0x0 >,
			             < 0xd 0x0 >,
			             < 0xe 0x0 >,
			             < 0xf 0x0 >,
			             < 0x10 0x0 >,
			             < 0x11 0x0 >,
			             < 0x2f 0x0 >;      /* in zephyr\dts\arm\st\h7\stm32h7.dtsi:934 */
			clocks = < &rcc 0xd8 0x1 >;     /* in zephyr\dts\arm\st\h7\stm32h7.dtsi:936 */
			st,mem2mem;                     /* in zephyr\dts\arm\st\h7\stm32h7.dtsi:937 */
			dma-offset = < 0x0 >;           /* in zephyr\dts\arm\st\h7\stm32h7.dtsi:938 */
			dma-requests = < 0x8 >;         /* in zephyr\dts\arm\st\h7\stm32h7.dtsi:939 */
			status = "okay";                /* in template_zephyr\boards\nucleo_h723zg.overlay:6 */
			phandle = < 0x22 >;             /* in zephyr\dts\arm\st\h7\stm32h7.dtsi:1090 */
		};

		/* node '/soc/dma@40020400' defined in zephyr\dts\arm\st\h7\stm32h7.dtsi:943 */
		dma2: dma@40020400 {
			compatible = "st,stm32-dma-v1"; /* in zephyr\dts\arm\st\h7\stm32h7.dtsi:944 */
			#dma-cells = < 0x4 >;           /* in zephyr\dts\arm\st\h7\stm32h7.dtsi:945 */
			reg = < 0x40020400 0x400 >;     /* in zephyr\dts\arm\st\h7\stm32h7.dtsi:946 */
			interrupts = < 0x38 0x0 >,
			             < 0x39 0x0 >,
			             < 0x3a 0x0 >,
			             < 0x3b 0x0 >,
			             < 0x3c 0x0 >,
			             < 0x44 0x0 >,
			             < 0x45 0x0 >,
			             < 0x46 0x0 >;      /* in zephyr\dts\arm\st\h7\stm32h7.dtsi:947 */
			clocks = < &rcc 0xd8 0x2 >;     /* in zephyr\dts\arm\st\h7\stm32h7.dtsi:949 */
			st,mem2mem;                     /* in zephyr\dts\arm\st\h7\stm32h7.dtsi:950 */
			dma-offset = < 0x8 >;           /* in zephyr\dts\arm\st\h7\stm32h7.dtsi:951 */
			dma-requests = < 0x8 >;         /* in zephyr\dts\arm\st\h7\stm32h7.dtsi:952 */
			status = "disabled";            /* in zephyr\dts\arm\st\h7\stm32h7.dtsi:953 */
		};

		/* node '/soc/bdma@58025400' defined in zephyr\dts\arm\st\h7\stm32h7.dtsi:956 */
		bdma1: bdma@58025400 {
			compatible = "st,stm32-bdma";    /* in zephyr\dts\arm\st\h7\stm32h7.dtsi:957 */
			#dma-cells = < 0x4 >;            /* in zephyr\dts\arm\st\h7\stm32h7.dtsi:958 */
			reg = < 0x58025400 0x400 >;      /* in zephyr\dts\arm\st\h7\stm32h7.dtsi:959 */
			interrupts = < 0x81 0x0 >,
			             < 0x82 0x0 >,
			             < 0x83 0x0 >,
			             < 0x84 0x0 >,
			             < 0x85 0x0 >,
			             < 0x86 0x0 >,
			             < 0x87 0x0 >,
			             < 0x88 0x0 >;       /* in zephyr\dts\arm\st\h7\stm32h7.dtsi:960 */
			clocks = < &rcc 0xe0 0x200000 >; /* in zephyr\dts\arm\st\h7\stm32h7.dtsi:962 */
			st,mem2mem;                      /* in zephyr\dts\arm\st\h7\stm32h7.dtsi:963 */
			dma-offset = < 0x0 >;            /* in zephyr\dts\arm\st\h7\stm32h7.dtsi:964 */
			dma-requests = < 0x8 >;          /* in zephyr\dts\arm\st\h7\stm32h7.dtsi:965 */
			status = "disabled";             /* in zephyr\dts\arm\st\h7\stm32h7.dtsi:966 */
		};

		/* node '/soc/dmamux@40020800' defined in zephyr\dts\arm\st\h7\stm32h7.dtsi:969 */
		dmamux1: dmamux@40020800 {
			compatible = "st,stm32-dmamux"; /* in zephyr\dts\arm\st\h7\stm32h7.dtsi:970 */
			#dma-cells = < 0x3 >;           /* in zephyr\dts\arm\st\h7\stm32h7.dtsi:971 */
			reg = < 0x40020800 0x400 >;     /* in zephyr\dts\arm\st\h7\stm32h7.dtsi:972 */
			interrupts = < 0x66 0x0 >;      /* in zephyr\dts\arm\st\h7\stm32h7.dtsi:973 */
			clocks = < &rcc 0xd8 0x1 >;     /* in zephyr\dts\arm\st\h7\stm32h7.dtsi:975 */
			dma-channels = < 0x10 >;        /* in zephyr\dts\arm\st\h7\stm32h7.dtsi:976 */
			dma-generators = < 0x8 >;       /* in zephyr\dts\arm\st\h7\stm32h7.dtsi:977 */
			dma-requests = < 0x81 >;        /* in zephyr\dts\arm\st\h7\stm32h723.dtsi:60 */
			status = "okay";                /* in template_zephyr\boards\nucleo_h723zg.overlay:2 */
			phandle = < 0x14 >;             /* in template_zephyr\boards\nucleo_h723zg.overlay:15 */
		};

		/* node '/soc/dmamux@58025800' defined in zephyr\dts\arm\st\h7\stm32h7.dtsi:985 */
		dmamux2: dmamux@58025800 {
			compatible = "st,stm32-dmamux";  /* in zephyr\dts\arm\st\h7\stm32h7.dtsi:986 */
			#dma-cells = < 0x3 >;            /* in zephyr\dts\arm\st\h7\stm32h7.dtsi:987 */
			reg = < 0x58025800 0x400 >;      /* in zephyr\dts\arm\st\h7\stm32h7.dtsi:988 */
			interrupts = < 0x80 0x0 >;       /* in zephyr\dts\arm\st\h7\stm32h7.dtsi:989 */
			clocks = < &rcc 0xe0 0x200000 >; /* in zephyr\dts\arm\st\h7\stm32h7.dtsi:991 */
			dma-channels = < 0x8 >;          /* in zephyr\dts\arm\st\h7\stm32h7.dtsi:992 */
			dma-generators = < 0x8 >;        /* in zephyr\dts\arm\st\h7\stm32h7.dtsi:993 */
			status = "disabled";             /* in zephyr\dts\arm\st\h7\stm32h7.dtsi:994 */
			dma-requests = < 0x81 >;         /* in zephyr\dts\arm\st\h7\stm32h723.dtsi:64 */
		};

		/* node '/soc/rng@48021800' defined in zephyr\dts\arm\st\h7\stm32h7.dtsi:1001 */
		rng: rng@48021800 {
			compatible = "st,stm32-rng";        /* in zephyr\dts\arm\st\h7\stm32h7.dtsi:1002 */
			reg = < 0x48021800 0x400 >;         /* in zephyr\dts\arm\st\h7\stm32h7.dtsi:1003 */
			clocks = < &rcc 0xdc 0x40 >;        /* in zephyr\dts\arm\st\h7\stm32h7.dtsi:1004 */
			interrupts = < 0x50 0x0 >;          /* in zephyr\dts\arm\st\h7\stm32h7.dtsi:1005 */
			health-test-magic = < 0x17590abc >; /* in zephyr\dts\arm\st\h7\stm32h723.dtsi:68 */
			health-test-config = < 0xaa74 >;    /* in zephyr\dts\arm\st\h7\stm32h723.dtsi:69 */
			status = "okay";                    /* in zephyr\boards\st\nucleo_h723zg\nucleo_h723zg.dts:214 */
		};

		/* node '/soc/sdmmc@52007000' defined in zephyr\dts\arm\st\h7\stm32h7.dtsi:1009 */
		sdmmc1: sdmmc@52007000 {
			compatible = "st,stm32-sdmmc";  /* in zephyr\dts\arm\st\h7\stm32h7.dtsi:1010 */
			reg = < 0x52007000 0x400 >;     /* in zephyr\dts\arm\st\h7\stm32h7.dtsi:1011 */
			clocks = < &rcc 0xd4 0x10000 >,
			         < &rcc 0x9 0x50004c >; /* in zephyr\dts\arm\st\h7\stm32h7.dtsi:1012 */
			resets = < &rctl 0xf90 >;       /* in zephyr\dts\arm\st\h7\stm32h7.dtsi:1014 */
			interrupts = < 0x31 0x0 >;      /* in zephyr\dts\arm\st\h7\stm32h7.dtsi:1015 */
			status = "disabled";            /* in zephyr\dts\arm\st\h7\stm32h7.dtsi:1016 */
		};

		/* node '/soc/sdmmc@48022400' defined in zephyr\dts\arm\st\h7\stm32h7.dtsi:1019 */
		sdmmc2: sdmmc@48022400 {
			compatible = "st,stm32-sdmmc";  /* in zephyr\dts\arm\st\h7\stm32h7.dtsi:1020 */
			reg = < 0x48022400 0x400 >;     /* in zephyr\dts\arm\st\h7\stm32h7.dtsi:1021 */
			clocks = < &rcc 0xdc 0x200 >,
			         < &rcc 0x9 0x50004c >; /* in zephyr\dts\arm\st\h7\stm32h7.dtsi:1022 */
			resets = < &rctl 0x1089 >;      /* in zephyr\dts\arm\st\h7\stm32h7.dtsi:1024 */
			interrupts = < 0x7c 0x0 >;      /* in zephyr\dts\arm\st\h7\stm32h7.dtsi:1025 */
			status = "disabled";            /* in zephyr\dts\arm\st\h7\stm32h7.dtsi:1026 */
		};

		/* node '/soc/ethernet@40028000' defined in zephyr\dts\arm\st\h7\stm32h7.dtsi:1029 */
		ethernet@40028000 {
			reg = < 0x40028000 0x8000 >;                 /* in zephyr\dts\arm\st\h7\stm32h7.dtsi:1030 */
			compatible = "st,stm32-ethernet-controller"; /* in zephyr\dts\arm\st\h7\stm32h7.dtsi:1031 */
			clock-names = "stm-eth";                     /* in zephyr\dts\arm\st\h7\stm32h7.dtsi:1032 */
			clocks = < &rcc 0xd8 0x8000 >;               /* in zephyr\dts\arm\st\h7\stm32h7.dtsi:1033 */

			/* node '/soc/ethernet@40028000/ethernet' defined in zephyr\dts\arm\st\h7\stm32h7.dtsi:1035 */
			mac: ethernet {
				compatible = "st,stm32h7-ethernet",
				             "st,stm32-ethernet";                                                                         /* in zephyr\dts\arm\st\h7\stm32h7.dtsi:1036 */
				interrupts = < 0x3d 0x0 >;                                                                                /* in zephyr\dts\arm\st\h7\stm32h7.dtsi:1037 */
				clock-names = "mac-clk-tx",
				              "mac-clk-rx";                                                                               /* in zephyr\dts\arm\st\h7\stm32h7.dtsi:1038 */
				clocks = < &rcc 0xd8 0x10000 >,
				         < &rcc 0xd8 0x20000 >;                                                                           /* in zephyr\dts\arm\st\h7\stm32h7.dtsi:1039 */
				status = "okay";                                                                                          /* in zephyr\boards\st\nucleo_h723zg\nucleo_h723zg.dts:183 */
				pinctrl-0 = < &eth_ref_clk_pa1 &eth_crs_dv_pa7 &eth_rxd0_pc4 &eth_rxd1_pc5 &eth_tx_en_pg11 &eth_txd0_pg13
				              &eth_txd1_pb13 >;                                                                           /* in zephyr\boards\st\nucleo_h723zg\nucleo_h723zg.dts:184 */
				pinctrl-names = "default";                                                                                /* in zephyr\boards\st\nucleo_h723zg\nucleo_h723zg.dts:191 */
				phy-connection-type = "rmii";                                                                             /* in zephyr\boards\st\nucleo_h723zg\nucleo_h723zg.dts:192 */
				phy-handle = < &eth_phy >;                                                                                /* in zephyr\boards\st\nucleo_h723zg\nucleo_h723zg.dts:193 */
			};

			/* node '/soc/ethernet@40028000/mdio' defined in zephyr\dts\arm\st\h7\stm32h7.dtsi:1044 */
			mdio: mdio {
				compatible = "st,stm32-mdio";               /* in zephyr\dts\arm\st\h7\stm32h7.dtsi:1045 */
				#address-cells = < 0x1 >;                   /* in zephyr\dts\arm\st\h7\stm32h7.dtsi:1046 */
				#size-cells = < 0x0 >;                      /* in zephyr\dts\arm\st\h7\stm32h7.dtsi:1047 */
				status = "okay";                            /* in zephyr\boards\st\nucleo_h723zg\nucleo_h723zg.dts:197 */
				pinctrl-0 = < &eth_mdio_pa2 &eth_mdc_pc1 >; /* in zephyr\boards\st\nucleo_h723zg\nucleo_h723zg.dts:198 */
				pinctrl-names = "default";                  /* in zephyr\boards\st\nucleo_h723zg\nucleo_h723zg.dts:199 */

				/* node '/soc/ethernet@40028000/mdio/ethernet-phy@0' defined in zephyr\boards\st\nucleo_h723zg\nucleo_h723zg.dts:201 */
				eth_phy: ethernet-phy@0 {
					compatible = "ethernet-phy"; /* in zephyr\boards\st\nucleo_h723zg\nucleo_h723zg.dts:202 */
					reg = < 0x0 >;               /* in zephyr\boards\st\nucleo_h723zg\nucleo_h723zg.dts:203 */
					phandle = < 0x1f >;          /* in zephyr\boards\st\nucleo_h723zg\nucleo_h723zg.dts:193 */
				};
			};
		};

		/* node '/soc/memory-controller@52004000' defined in zephyr\dts\arm\st\h7\stm32h7.dtsi:1052 */
		fmc: memory-controller@52004000 {
			compatible = "st,stm32h7-fmc"; /* in zephyr\dts\arm\st\h7\stm32h7.dtsi:1053 */
			reg = < 0x52004000 0x400 >;    /* in zephyr\dts\arm\st\h7\stm32h7.dtsi:1054 */
			clocks = < &rcc 0xd4 0x1000 >; /* in zephyr\dts\arm\st\h7\stm32h7.dtsi:1055 */
			status = "disabled";           /* in zephyr\dts\arm\st\h7\stm32h7.dtsi:1056 */

			/* node '/soc/memory-controller@52004000/sdram' defined in zephyr\dts\arm\st\h7\stm32h7.dtsi:1058 */
			sdram: sdram {
				compatible = "st,stm32-fmc-sdram"; /* in zephyr\dts\arm\st\h7\stm32h7.dtsi:1059 */
				#address-cells = < 0x1 >;          /* in zephyr\dts\arm\st\h7\stm32h7.dtsi:1060 */
				#size-cells = < 0x0 >;             /* in zephyr\dts\arm\st\h7\stm32h7.dtsi:1061 */
				status = "disabled";               /* in zephyr\dts\arm\st\h7\stm32h7.dtsi:1062 */
			};
		};

		/* node '/soc/memory@38800000' defined in zephyr\dts\arm\st\h7\stm32h7.dtsi:1066 */
		backup_sram: memory@38800000 {
			compatible = "zephyr,memory-region",
			             "st,stm32-backup-sram";  /* in zephyr\dts\arm\st\h7\stm32h7.dtsi:1067 */
			reg = < 0x38800000 0x1000 >;          /* in zephyr\dts\arm\st\h7\stm32h7.dtsi:1068 */
			clocks = < &rcc 0xe0 0x10000000 >;    /* in zephyr\dts\arm\st\h7\stm32h7.dtsi:1069 */
			zephyr,memory-region = "BACKUP_SRAM"; /* in zephyr\dts\arm\st\h7\stm32h7.dtsi:1070 */
			status = "okay";                      /* in zephyr\boards\st\nucleo_h723zg\nucleo_h723zg.dts:168 */
		};

		/* node '/soc/spi@52005000' defined in zephyr\dts\arm\st\h7\stm32h7.dtsi:1074 */
		quadspi: octospi1: spi@52005000 {
			compatible = "st,stm32-ospi";    /* in zephyr\dts\arm\st\h7\stm32h723.dtsi:97 */
			reg = < 0x52005000 0x1000 >,
			      < 0x90000000 0x10000000 >; /* in zephyr\dts\arm\st\h7\stm32h723.dtsi:98 */
			interrupts = < 0x5c 0x0 >;       /* in zephyr\dts\arm\st\h7\stm32h723.dtsi:99 */
			clock-names = "ospix",
			              "ospi-ker";        /* in zephyr\dts\arm\st\h7\stm32h723.dtsi:100 */
			clocks = < &rcc 0xd4 0x4000 >,
			         < &rcc 0x9 0x8c4004c >; /* in zephyr\dts\arm\st\h7\stm32h723.dtsi:101 */
			#address-cells = < 0x1 >;        /* in zephyr\dts\arm\st\h7\stm32h723.dtsi:103 */
			#size-cells = < 0x0 >;           /* in zephyr\dts\arm\st\h7\stm32h723.dtsi:104 */
			status = "disabled";             /* in zephyr\dts\arm\st\h7\stm32h723.dtsi:105 */
		};

		/* node '/soc/dcmi@48020000' defined in zephyr\dts\arm\st\h7\stm32h7.dtsi:1084 */
		dcmi: dcmi@48020000 {
			compatible = "st,stm32-dcmi";          /* in zephyr\dts\arm\st\h7\stm32h7.dtsi:1085 */
			reg = < 0x48020000 0x400 >;            /* in zephyr\dts\arm\st\h7\stm32h7.dtsi:1086 */
			interrupts = < 0x4e 0x0 >;             /* in zephyr\dts\arm\st\h7\stm32h7.dtsi:1087 */
			interrupt-names = "dcmi";              /* in zephyr\dts\arm\st\h7\stm32h7.dtsi:1088 */
			clocks = < &rcc 0xdc 0x1 >;            /* in zephyr\dts\arm\st\h7\stm32h7.dtsi:1089 */
			dmas = < &dma1 0x0 0x4b 0x24480 0x0 >; /* in zephyr\dts\arm\st\h7\stm32h7.dtsi:1090 */
			status = "disabled";                   /* in zephyr\dts\arm\st\h7\stm32h7.dtsi:1093 */
		};

		/* node '/soc/serial@40011800' defined in zephyr\dts\arm\st\h7\stm32h723.dtsi:27 */
		uart9: serial@40011800 {
			compatible = "st,stm32-uart"; /* in zephyr\dts\arm\st\h7\stm32h723.dtsi:28 */
			reg = < 0x40011800 0x400 >;   /* in zephyr\dts\arm\st\h7\stm32h723.dtsi:29 */
			clocks = < &rcc 0xf0 0x40 >;  /* in zephyr\dts\arm\st\h7\stm32h723.dtsi:30 */
			resets = < &rctl 0x1306 >;    /* in zephyr\dts\arm\st\h7\stm32h723.dtsi:31 */
			interrupts = < 0x9b 0x0 >;    /* in zephyr\dts\arm\st\h7\stm32h723.dtsi:32 */
			status = "disabled";          /* in zephyr\dts\arm\st\h7\stm32h723.dtsi:33 */
		};

		/* node '/soc/serial@40011c00' defined in zephyr\dts\arm\st\h7\stm32h723.dtsi:36 */
		usart10: serial@40011c00 {
			compatible = "st,stm32-usart",
			             "st,stm32-uart";  /* in zephyr\dts\arm\st\h7\stm32h723.dtsi:37 */
			reg = < 0x40011c00 0x400 >;    /* in zephyr\dts\arm\st\h7\stm32h723.dtsi:38 */
			clocks = < &rcc 0xf0 0x80 >;   /* in zephyr\dts\arm\st\h7\stm32h723.dtsi:39 */
			resets = < &rctl 0x1307 >;     /* in zephyr\dts\arm\st\h7\stm32h723.dtsi:40 */
			interrupts = < 0x9c 0x0 >;     /* in zephyr\dts\arm\st\h7\stm32h723.dtsi:41 */
			status = "disabled";           /* in zephyr\dts\arm\st\h7\stm32h723.dtsi:42 */
		};

		/* node '/soc/usb@40040000' defined in zephyr\dts\arm\st\h7\stm32h723.dtsi:72 */
		usbotg_hs: zephyr_udc0: usb@40040000 {
			compatible = "st,stm32-otghs";                           /* in zephyr\dts\arm\st\h7\stm32h723.dtsi:73 */
			reg = < 0x40040000 0x40000 >;                            /* in zephyr\dts\arm\st\h7\stm32h723.dtsi:74 */
			interrupts = < 0x4d 0x0 >,
			             < 0x4a 0x0 >,
			             < 0x4b 0x0 >;                               /* in zephyr\dts\arm\st\h7\stm32h723.dtsi:75 */
			interrupt-names = "otghs",
			                  "ep1_out",
			                  "ep1_in";                              /* in zephyr\dts\arm\st\h7\stm32h723.dtsi:76 */
			num-bidir-endpoints = < 0x9 >;                           /* in zephyr\dts\arm\st\h7\stm32h723.dtsi:77 */
			ram-size = < 0x1000 >;                                   /* in zephyr\dts\arm\st\h7\stm32h723.dtsi:78 */
			maximum-speed = "full-speed";                            /* in zephyr\dts\arm\st\h7\stm32h723.dtsi:79 */
			clocks = < &rcc 0xd8 0x2000000 >,
			         < &rcc 0x5 0x18d40054 >;                        /* in zephyr\dts\arm\st\h7\stm32h723.dtsi:80 */
			phys = < &otghs_fs_phy >;                                /* in zephyr\dts\arm\st\h7\stm32h723.dtsi:82 */
			pinctrl-0 = < &usb_otg_hs_dm_pa11 &usb_otg_hs_dp_pa12 >; /* in zephyr\boards\st\nucleo_h723zg\nucleo_h723zg.dts:208 */
			pinctrl-names = "default";                               /* in zephyr\boards\st\nucleo_h723zg\nucleo_h723zg.dts:209 */
			status = "okay";                                         /* in zephyr\boards\st\nucleo_h723zg\nucleo_h723zg.dts:210 */
		};

		/* node '/soc/display-controller@50001000' defined in zephyr\dts\arm\st\h7\stm32h723.dtsi:86 */
		ltdc: display-controller@50001000 {
			compatible = "st,stm32-ltdc"; /* in zephyr\dts\arm\st\h7\stm32h723.dtsi:87 */
			reg = < 0x50001000 0x200 >;   /* in zephyr\dts\arm\st\h7\stm32h723.dtsi:88 */
			interrupts = < 0x58 0x0 >,
			             < 0x59 0x0 >;    /* in zephyr\dts\arm\st\h7\stm32h723.dtsi:89 */
			interrupt-names = "ltdc",
			                  "ltdc_er";  /* in zephyr\dts\arm\st\h7\stm32h723.dtsi:90 */
			clocks = < &rcc 0xe4 0x8 >;   /* in zephyr\dts\arm\st\h7\stm32h723.dtsi:91 */
			resets = < &rctl 0x1183 >;    /* in zephyr\dts\arm\st\h7\stm32h723.dtsi:92 */
			status = "disabled";          /* in zephyr\dts\arm\st\h7\stm32h723.dtsi:93 */
		};

		/* node '/soc/spi@5200a000' defined in zephyr\dts\arm\st\h7\stm32h723.dtsi:108 */
		octospi2: spi@5200a000 {
			compatible = "st,stm32-ospi";    /* in zephyr\dts\arm\st\h7\stm32h723.dtsi:109 */
			reg = < 0x5200a000 0x1000 >,
			      < 0x70000000 0x10000000 >; /* in zephyr\dts\arm\st\h7\stm32h723.dtsi:110 */
			interrupts = < 0x96 0x0 >;       /* in zephyr\dts\arm\st\h7\stm32h723.dtsi:111 */
			clock-names = "ospix",
			              "ospi-ker";        /* in zephyr\dts\arm\st\h7\stm32h723.dtsi:112 */
			clocks = < &rcc 0xd4 0x80000 >,
			         < &rcc 0x9 0x8c4004c >; /* in zephyr\dts\arm\st\h7\stm32h723.dtsi:113 */
			#address-cells = < 0x1 >;        /* in zephyr\dts\arm\st\h7\stm32h723.dtsi:115 */
			#size-cells = < 0x0 >;           /* in zephyr\dts\arm\st\h7\stm32h723.dtsi:116 */
			status = "disabled";             /* in zephyr\dts\arm\st\h7\stm32h723.dtsi:117 */
		};

		/* node '/soc/can@4000d400' defined in zephyr\dts\arm\st\h7\stm32h723.dtsi:120 */
		fdcan3: can@4000d400 {
			compatible = "st,stm32h7-fdcan";                         /* in zephyr\dts\arm\st\h7\stm32h723.dtsi:121 */
			reg = < 0x4000d400 0x400 >,
			      < 0x4000ac00 0x9f0 >;                              /* in zephyr\dts\arm\st\h7\stm32h723.dtsi:122 */
			reg-names = "m_can",
			            "message_ram";                               /* in zephyr\dts\arm\st\h7\stm32h723.dtsi:123 */
			clocks = < &rcc 0xec 0x100 >;                            /* in zephyr\dts\arm\st\h7\stm32h723.dtsi:124 */
			interrupts = < 0x9f 0x0 >,
			             < 0xa0 0x0 >,
			             < 0x3f 0x0 >;                               /* in zephyr\dts\arm\st\h7\stm32h723.dtsi:125 */
			interrupt-names = "int0",
			                  "int1",
			                  "calib";                               /* in zephyr\dts\arm\st\h7\stm32h723.dtsi:126 */
			bosch,mram-cfg = < 0x6a0 0x1c 0x8 0x3 0x3 0x0 0x3 0x3 >; /* in zephyr\dts\arm\st\h7\stm32h723.dtsi:127 */
			status = "disabled";                                     /* in zephyr\dts\arm\st\h7\stm32h723.dtsi:128 */
		};

		/* node '/soc/timers@4000e000' defined in zephyr\dts\arm\st\h7\stm32h723.dtsi:139 */
		timers23: timers@4000e000 {
			compatible = "st,stm32-timers";   /* in zephyr\dts\arm\st\h7\stm32h723.dtsi:140 */
			reg = < 0x4000e000 0x400 >;       /* in zephyr\dts\arm\st\h7\stm32h723.dtsi:141 */
			clocks = < &rcc 0xec 0x1000000 >; /* in zephyr\dts\arm\st\h7\stm32h723.dtsi:142 */
			resets = < &rctl 0x1298 >;        /* in zephyr\dts\arm\st\h7\stm32h723.dtsi:143 */
			interrupts = < 0xa1 0x0 >;        /* in zephyr\dts\arm\st\h7\stm32h723.dtsi:144 */
			interrupt-names = "global";       /* in zephyr\dts\arm\st\h7\stm32h723.dtsi:145 */
			st,prescaler = < 0x0 >;           /* in zephyr\dts\arm\st\h7\stm32h723.dtsi:146 */
			status = "disabled";              /* in zephyr\dts\arm\st\h7\stm32h723.dtsi:147 */

			/* node '/soc/timers@4000e000/pwm' defined in zephyr\dts\arm\st\h7\stm32h723.dtsi:149 */
			pwm {
				compatible = "st,stm32-pwm"; /* in zephyr\dts\arm\st\h7\stm32h723.dtsi:150 */
				status = "disabled";         /* in zephyr\dts\arm\st\h7\stm32h723.dtsi:151 */
				#pwm-cells = < 0x3 >;        /* in zephyr\dts\arm\st\h7\stm32h723.dtsi:152 */
			};

			/* node '/soc/timers@4000e000/counter' defined in zephyr\dts\arm\st\h7\stm32h723.dtsi:155 */
			counter {
				compatible = "st,stm32-counter"; /* in zephyr\dts\arm\st\h7\stm32h723.dtsi:156 */
				status = "disabled";             /* in zephyr\dts\arm\st\h7\stm32h723.dtsi:157 */
			};
		};

		/* node '/soc/timers@4000e400' defined in zephyr\dts\arm\st\h7\stm32h723.dtsi:161 */
		timers24: timers@4000e400 {
			compatible = "st,stm32-timers";   /* in zephyr\dts\arm\st\h7\stm32h723.dtsi:162 */
			reg = < 0x4000e400 0x400 >;       /* in zephyr\dts\arm\st\h7\stm32h723.dtsi:163 */
			clocks = < &rcc 0xec 0x2000000 >; /* in zephyr\dts\arm\st\h7\stm32h723.dtsi:164 */
			resets = < &rctl 0x1299 >;        /* in zephyr\dts\arm\st\h7\stm32h723.dtsi:165 */
			interrupts = < 0xa2 0x0 >;        /* in zephyr\dts\arm\st\h7\stm32h723.dtsi:166 */
			interrupt-names = "global";       /* in zephyr\dts\arm\st\h7\stm32h723.dtsi:167 */
			st,prescaler = < 0x0 >;           /* in zephyr\dts\arm\st\h7\stm32h723.dtsi:168 */
			status = "disabled";              /* in zephyr\dts\arm\st\h7\stm32h723.dtsi:169 */

			/* node '/soc/timers@4000e400/pwm' defined in zephyr\dts\arm\st\h7\stm32h723.dtsi:171 */
			pwm {
				compatible = "st,stm32-pwm"; /* in zephyr\dts\arm\st\h7\stm32h723.dtsi:172 */
				status = "disabled";         /* in zephyr\dts\arm\st\h7\stm32h723.dtsi:173 */
				#pwm-cells = < 0x3 >;        /* in zephyr\dts\arm\st\h7\stm32h723.dtsi:174 */
			};

			/* node '/soc/timers@4000e400/counter' defined in zephyr\dts\arm\st\h7\stm32h723.dtsi:177 */
			counter {
				compatible = "st,stm32-counter"; /* in zephyr\dts\arm\st\h7\stm32h723.dtsi:178 */
				status = "disabled";             /* in zephyr\dts\arm\st\h7\stm32h723.dtsi:179 */
			};
		};

		/* node '/soc/digi_dietemp@58006800' defined in zephyr\dts\arm\st\h7\stm32h723.dtsi:183 */
		digi_die_temp: digi_dietemp@58006800 {
			compatible = "st,stm32-digi-temp"; /* in zephyr\dts\arm\st\h7\stm32h723.dtsi:184 */
			reg = < 0x58006800 0x400 >;        /* in zephyr\dts\arm\st\h7\stm32h723.dtsi:185 */
			interrupts = < 0x93 0x0 >;         /* in zephyr\dts\arm\st\h7\stm32h723.dtsi:186 */
			interrupt-names = "digi_temp";     /* in zephyr\dts\arm\st\h7\stm32h723.dtsi:187 */
			clocks = < &rcc 0xf4 0x4000000 >;  /* in zephyr\dts\arm\st\h7\stm32h723.dtsi:188 */
			status = "disabled";               /* in zephyr\dts\arm\st\h7\stm32h723.dtsi:189 */
		};
	};

	/* node '/cpus' defined in zephyr\dts\arm\st\h7\stm32h7.dtsi:31 */
	cpus {
		#address-cells = < 0x1 >; /* in zephyr\dts\arm\st\h7\stm32h7.dtsi:32 */
		#size-cells = < 0x0 >;    /* in zephyr\dts\arm\st\h7\stm32h7.dtsi:33 */

		/* node '/cpus/cpu@0' defined in zephyr\dts\arm\st\h7\stm32h7.dtsi:35 */
		cpu0: cpu@0 {
			device_type = "cpu";          /* in zephyr\dts\arm\st\h7\stm32h7.dtsi:36 */
			compatible = "arm,cortex-m7"; /* in zephyr\dts\arm\st\h7\stm32h7.dtsi:37 */
			reg = < 0x0 >;                /* in zephyr\dts\arm\st\h7\stm32h7.dtsi:38 */
			#address-cells = < 0x1 >;     /* in zephyr\dts\arm\st\h7\stm32h7.dtsi:39 */
			#size-cells = < 0x1 >;        /* in zephyr\dts\arm\st\h7\stm32h7.dtsi:40 */

			/* node '/cpus/cpu@0/mpu@e000ed90' defined in zephyr\dts\arm\st\h7\stm32h7.dtsi:42 */
			mpu: mpu@e000ed90 {
				compatible = "arm,armv7m-mpu"; /* in zephyr\dts\arm\st\h7\stm32h7.dtsi:43 */
				reg = < 0xe000ed90 0x40 >;     /* in zephyr\dts\arm\st\h7\stm32h7.dtsi:44 */
			};
		};
	};

	/* node '/memory@90000000' defined in zephyr\dts\arm\st\h7\stm32h7.dtsi:49 */
	ext_memory: memory@90000000 {
		compatible = "zephyr,memory-region"; /* in zephyr\dts\arm\st\h7\stm32h7.dtsi:50 */
		reg = < 0x90000000 0x10000000 >;     /* in zephyr\dts\arm\st\h7\stm32h7.dtsi:51 */
		zephyr,memory-region = "EXTMEM";     /* in zephyr\dts\arm\st\h7\stm32h7.dtsi:52 */
		zephyr,memory-attr = < 0x2000000 >;  /* in zephyr\dts\arm\st\h7\stm32h7.dtsi:53 */
	};

	/* node '/clocks' defined in zephyr\dts\arm\st\h7\stm32h7.dtsi:56 */
	clocks {
		#address-cells = < 0x1 >; /* in zephyr\dts\arm\st\h7\stm32h7.dtsi:57 */
		#size-cells = < 0x0 >;    /* in zephyr\dts\arm\st\h7\stm32h7.dtsi:58 */

		/* node '/clocks/clk-hse' defined in zephyr\dts\arm\st\h7\stm32h7.dtsi:60 */
		clk_hse: clk-hse {
			#clock-cells = < 0x0 >;            /* in zephyr\dts\arm\st\h7\stm32h7.dtsi:61 */
			compatible = "st,stm32-hse-clock"; /* in zephyr\dts\arm\st\h7\stm32h7.dtsi:62 */
			hse-bypass;                        /* in zephyr\boards\st\nucleo_h723zg\nucleo_h723zg.dts:86 */
			clock-frequency = < 0x7a1200 >;    /* in zephyr\boards\st\nucleo_h723zg\nucleo_h723zg.dts:87 */
			status = "okay";                   /* in zephyr\boards\st\nucleo_h723zg\nucleo_h723zg.dts:88 */
			phandle = < 0x26 >;                /* in zephyr\boards\st\nucleo_h723zg\nucleo_h723zg.dts:101 */
		};

		/* node '/clocks/clk-hsi' defined in zephyr\dts\arm\st\h7\stm32h7.dtsi:66 */
		clk_hsi: clk-hsi {
			#clock-cells = < 0x0 >;              /* in zephyr\dts\arm\st\h7\stm32h7.dtsi:67 */
			compatible = "st,stm32h7-hsi-clock"; /* in zephyr\dts\arm\st\h7\stm32h7.dtsi:68 */
			hsi-div = < 0x1 >;                   /* in zephyr\dts\arm\st\h7\stm32h7.dtsi:69 */
			clock-frequency = < 0x3d09000 >;     /* in zephyr\dts\arm\st\h7\stm32h7.dtsi:70 */
			status = "disabled";                 /* in zephyr\dts\arm\st\h7\stm32h7.dtsi:71 */
		};

		/* node '/clocks/clk-hsi48' defined in zephyr\dts\arm\st\h7\stm32h7.dtsi:74 */
		clk_hsi48: clk-hsi48 {
			#clock-cells = < 0x0 >;          /* in zephyr\dts\arm\st\h7\stm32h7.dtsi:75 */
			compatible = "fixed-clock";      /* in zephyr\dts\arm\st\h7\stm32h7.dtsi:76 */
			clock-frequency = < 0x2dc6c00 >; /* in zephyr\dts\arm\st\h7\stm32h7.dtsi:77 */
			status = "okay";                 /* in zephyr\boards\st\nucleo_h723zg\nucleo_h723zg.dts:82 */
		};

		/* node '/clocks/clk-csi' defined in zephyr\dts\arm\st\h7\stm32h7.dtsi:81 */
		clk_csi: clk-csi {
			#clock-cells = < 0x0 >;         /* in zephyr\dts\arm\st\h7\stm32h7.dtsi:82 */
			compatible = "fixed-clock";     /* in zephyr\dts\arm\st\h7\stm32h7.dtsi:83 */
			clock-frequency = < 0x3d0900 >; /* in zephyr\dts\arm\st\h7\stm32h7.dtsi:84 */
			status = "disabled";            /* in zephyr\dts\arm\st\h7\stm32h7.dtsi:85 */
		};

		/* node '/clocks/clk-lse' defined in zephyr\dts\arm\st\h7\stm32h7.dtsi:88 */
		clk_lse: clk-lse {
			#clock-cells = < 0x0 >;            /* in zephyr\dts\arm\st\h7\stm32h7.dtsi:89 */
			compatible = "st,stm32-lse-clock"; /* in zephyr\dts\arm\st\h7\stm32h7.dtsi:90 */
			clock-frequency = < 0x8000 >;      /* in zephyr\dts\arm\st\h7\stm32h7.dtsi:91 */
			driving-capability = < 0x0 >;      /* in zephyr\dts\arm\st\h7\stm32h7.dtsi:92 */
			status = "okay";                   /* in zephyr\boards\st\nucleo_h723zg\nucleo_h723zg.dts:92 */
		};

		/* node '/clocks/clk-lsi' defined in zephyr\dts\arm\st\h7\stm32h7.dtsi:96 */
		clk_lsi: clk-lsi {
			#clock-cells = < 0x0 >;       /* in zephyr\dts\arm\st\h7\stm32h7.dtsi:97 */
			compatible = "fixed-clock";   /* in zephyr\dts\arm\st\h7\stm32h7.dtsi:98 */
			clock-frequency = < 0x7d00 >; /* in zephyr\dts\arm\st\h7\stm32h7.dtsi:99 */
			status = "okay";              /* in zephyr\boards\st\nucleo_h723zg\nucleo_h723zg.dts:78 */
		};

		/* node '/clocks/pll@0' defined in zephyr\dts\arm\st\h7\stm32h7.dtsi:103 */
		pll: pll@0 {
			#clock-cells = < 0x0 >;              /* in zephyr\dts\arm\st\h7\stm32h7.dtsi:104 */
			compatible = "st,stm32h7-pll-clock"; /* in zephyr\dts\arm\st\h7\stm32h7.dtsi:105 */
			reg = < 0x0 >;                       /* in zephyr\dts\arm\st\h7\stm32h7.dtsi:106 */
			div-m = < 0x4 >;                     /* in zephyr\boards\st\nucleo_h723zg\nucleo_h723zg.dts:96 */
			mul-n = < 0x113 >;                   /* in zephyr\boards\st\nucleo_h723zg\nucleo_h723zg.dts:97 */
			div-p = < 0x1 >;                     /* in zephyr\boards\st\nucleo_h723zg\nucleo_h723zg.dts:98 */
			div-q = < 0x4 >;                     /* in zephyr\boards\st\nucleo_h723zg\nucleo_h723zg.dts:99 */
			div-r = < 0x2 >;                     /* in zephyr\boards\st\nucleo_h723zg\nucleo_h723zg.dts:100 */
			clocks = < &clk_hse >;               /* in zephyr\boards\st\nucleo_h723zg\nucleo_h723zg.dts:101 */
			status = "okay";                     /* in zephyr\boards\st\nucleo_h723zg\nucleo_h723zg.dts:102 */
			phandle = < 0x2 >;                   /* in zephyr\boards\st\nucleo_h723zg\nucleo_h723zg.dts:116 */
		};

		/* node '/clocks/pll@1' defined in zephyr\dts\arm\st\h7\stm32h7.dtsi:110 */
		pll2: pll@1 {
			#clock-cells = < 0x0 >;              /* in zephyr\dts\arm\st\h7\stm32h7.dtsi:111 */
			compatible = "st,stm32h7-pll-clock"; /* in zephyr\dts\arm\st\h7\stm32h7.dtsi:112 */
			reg = < 0x1 >;                       /* in zephyr\dts\arm\st\h7\stm32h7.dtsi:113 */
			div-m = < 0x1 >;                     /* in zephyr\boards\st\nucleo_h723zg\nucleo_h723zg.dts:106 */
			mul-n = < 0xa >;                     /* in zephyr\boards\st\nucleo_h723zg\nucleo_h723zg.dts:107 */
			div-p = < 0x1 >;                     /* in zephyr\boards\st\nucleo_h723zg\nucleo_h723zg.dts:108 */
			div-q = < 0x1 >;                     /* in zephyr\boards\st\nucleo_h723zg\nucleo_h723zg.dts:109 */
			div-r = < 0x1 >;                     /* in zephyr\boards\st\nucleo_h723zg\nucleo_h723zg.dts:110 */
			clocks = < &clk_hse >;               /* in zephyr\boards\st\nucleo_h723zg\nucleo_h723zg.dts:111 */
			status = "okay";                     /* in zephyr\boards\st\nucleo_h723zg\nucleo_h723zg.dts:112 */
		};

		/* node '/clocks/pll@2' defined in zephyr\dts\arm\st\h7\stm32h7.dtsi:117 */
		pll3: pll@2 {
			#clock-cells = < 0x0 >;              /* in zephyr\dts\arm\st\h7\stm32h7.dtsi:118 */
			compatible = "st,stm32h7-pll-clock"; /* in zephyr\dts\arm\st\h7\stm32h7.dtsi:119 */
			reg = < 0x2 >;                       /* in zephyr\dts\arm\st\h7\stm32h7.dtsi:120 */
			status = "disabled";                 /* in zephyr\dts\arm\st\h7\stm32h7.dtsi:121 */
		};

		/* node '/clocks/perck' defined in zephyr\dts\arm\st\h7\stm32h7.dtsi:124 */
		perck: perck {
			#clock-cells = < 0x0 >;            /* in zephyr\dts\arm\st\h7\stm32h7.dtsi:125 */
			compatible = "st,stm32-clock-mux"; /* in zephyr\dts\arm\st\h7\stm32h7.dtsi:126 */
			status = "disabled";               /* in zephyr\dts\arm\st\h7\stm32h7.dtsi:127 */
		};
	};

	/* node '/mcos' defined in zephyr\dts\arm\st\h7\stm32h7.dtsi:131 */
	mcos {

		/* node '/mcos/mco1' defined in zephyr\dts\arm\st\h7\stm32h7.dtsi:132 */
		mco1: mco1 {
			compatible = "st,stm32-clock-mco"; /* in zephyr\dts\arm\st\h7\stm32h7.dtsi:133 */
			status = "disabled";               /* in zephyr\dts\arm\st\h7\stm32h7.dtsi:134 */
		};

		/* node '/mcos/mco2' defined in zephyr\dts\arm\st\h7\stm32h7.dtsi:137 */
		mco2: mco2 {
			compatible = "st,stm32-clock-mco"; /* in zephyr\dts\arm\st\h7\stm32h7.dtsi:138 */
			status = "disabled";               /* in zephyr\dts\arm\st\h7\stm32h7.dtsi:139 */
		};
	};

	/* node '/dietemp' defined in zephyr\dts\arm\st\h7\stm32h7.dtsi:1097 */
	die_temp: dietemp {
		compatible = "st,stm32-temp-cal"; /* in zephyr\dts\arm\st\h7\stm32h7.dtsi:1098 */
		ts-cal1-addr = < 0x1ff1e820 >;    /* in zephyr\dts\arm\st\h7\stm32h7.dtsi:1099 */
		ts-cal2-addr = < 0x1ff1e840 >;    /* in zephyr\dts\arm\st\h7\stm32h7.dtsi:1100 */
		ts-cal1-temp = < 0x1e >;          /* in zephyr\dts\arm\st\h7\stm32h7.dtsi:1101 */
		ts-cal-vrefanalog = < 0xce4 >;    /* in zephyr\dts\arm\st\h7\stm32h7.dtsi:1103 */
		ts-cal-resolution = < 0x10 >;     /* in zephyr\dts\arm\st\h7\stm32h7.dtsi:1104 */
		status = "disabled";              /* in zephyr\dts\arm\st\h7\stm32h7.dtsi:1106 */
		io-channels = < &adc3 0x11 >;     /* in zephyr\dts\arm\st\h7\stm32h723.dtsi:240 */
		ts-cal2-temp = < 0x82 >;          /* in zephyr\dts\arm\st\h7\stm32h723.dtsi:241 */
	};

	/* node '/vbat' defined in zephyr\dts\arm\st\h7\stm32h7.dtsi:1109 */
	vbat: vbat {
		compatible = "st,stm32-vbat"; /* in zephyr\dts\arm\st\h7\stm32h7.dtsi:1110 */
		ratio = < 0x4 >;              /* in zephyr\dts\arm\st\h7\stm32h7.dtsi:1111 */
		status = "disabled";          /* in zephyr\dts\arm\st\h7\stm32h7.dtsi:1112 */
		io-channels = < &adc3 0x10 >; /* in zephyr\dts\arm\st\h7\stm32h723.dtsi:249 */
	};

	/* node '/vref' defined in zephyr\dts\arm\st\h7\stm32h7.dtsi:1115 */
	vref: vref {
		compatible = "st,stm32-vref";      /* in zephyr\dts\arm\st\h7\stm32h7.dtsi:1116 */
		vrefint-cal-addr = < 0x1ff1e860 >; /* in zephyr\dts\arm\st\h7\stm32h7.dtsi:1117 */
		vrefint-cal-mv = < 0xce4 >;        /* in zephyr\dts\arm\st\h7\stm32h7.dtsi:1118 */
		vrefint-cal-resolution = < 0x10 >; /* in zephyr\dts\arm\st\h7\stm32h7.dtsi:1119 */
		status = "disabled";               /* in zephyr\dts\arm\st\h7\stm32h7.dtsi:1120 */
		io-channels = < &adc3 0x12 >;      /* in zephyr\dts\arm\st\h7\stm32h723.dtsi:245 */
	};

	/* node '/smbus1' defined in zephyr\dts\arm\st\h7\stm32h7.dtsi:1123 */
	smbus1: smbus1 {
		compatible = "st,stm32-smbus"; /* in zephyr\dts\arm\st\h7\stm32h7.dtsi:1124 */
		#address-cells = < 0x1 >;      /* in zephyr\dts\arm\st\h7\stm32h7.dtsi:1125 */
		#size-cells = < 0x0 >;         /* in zephyr\dts\arm\st\h7\stm32h7.dtsi:1126 */
		i2c = < &i2c1 >;               /* in zephyr\dts\arm\st\h7\stm32h7.dtsi:1127 */
		status = "disabled";           /* in zephyr\dts\arm\st\h7\stm32h7.dtsi:1128 */
	};

	/* node '/smbus2' defined in zephyr\dts\arm\st\h7\stm32h7.dtsi:1131 */
	smbus2: smbus2 {
		compatible = "st,stm32-smbus"; /* in zephyr\dts\arm\st\h7\stm32h7.dtsi:1132 */
		#address-cells = < 0x1 >;      /* in zephyr\dts\arm\st\h7\stm32h7.dtsi:1133 */
		#size-cells = < 0x0 >;         /* in zephyr\dts\arm\st\h7\stm32h7.dtsi:1134 */
		i2c = < &i2c2 >;               /* in zephyr\dts\arm\st\h7\stm32h7.dtsi:1135 */
		status = "disabled";           /* in zephyr\dts\arm\st\h7\stm32h7.dtsi:1136 */
	};

	/* node '/smbus3' defined in zephyr\dts\arm\st\h7\stm32h7.dtsi:1139 */
	smbus3: smbus3 {
		compatible = "st,stm32-smbus"; /* in zephyr\dts\arm\st\h7\stm32h7.dtsi:1140 */
		#address-cells = < 0x1 >;      /* in zephyr\dts\arm\st\h7\stm32h7.dtsi:1141 */
		#size-cells = < 0x0 >;         /* in zephyr\dts\arm\st\h7\stm32h7.dtsi:1142 */
		i2c = < &i2c3 >;               /* in zephyr\dts\arm\st\h7\stm32h7.dtsi:1143 */
		status = "disabled";           /* in zephyr\dts\arm\st\h7\stm32h7.dtsi:1144 */
	};

	/* node '/smbus4' defined in zephyr\dts\arm\st\h7\stm32h7.dtsi:1147 */
	smbus4: smbus4 {
		compatible = "st,stm32-smbus"; /* in zephyr\dts\arm\st\h7\stm32h7.dtsi:1148 */
		#address-cells = < 0x1 >;      /* in zephyr\dts\arm\st\h7\stm32h7.dtsi:1149 */
		#size-cells = < 0x0 >;         /* in zephyr\dts\arm\st\h7\stm32h7.dtsi:1150 */
		i2c = < &i2c4 >;               /* in zephyr\dts\arm\st\h7\stm32h7.dtsi:1151 */
		status = "disabled";           /* in zephyr\dts\arm\st\h7\stm32h7.dtsi:1152 */
	};

	/* node '/memory@24000000' defined in zephyr\dts\arm\st\h7\stm32h723.dtsi:194 */
	sram0: memory@24000000 {
		reg = < 0x24000000 0x50000 >; /* in zephyr\dts\arm\st\h7\stm32h723.dtsi:195 */
		compatible = "mmio-sram";     /* in zephyr\dts\arm\st\h7\stm32h723.dtsi:196 */
	};

	/* node '/memory@30000000' defined in zephyr\dts\arm\st\h7\stm32h723.dtsi:200 */
	sram1: memory@30000000 {
		reg = < 0x30000000 0x4000 >;         /* in zephyr\dts\arm\st\h7\stm32h723.dtsi:201 */
		compatible = "zephyr,memory-region",
		             "mmio-sram";            /* in zephyr\dts\arm\st\h7\stm32h723.dtsi:202 */
		zephyr,memory-region = "SRAM1";      /* in zephyr\dts\arm\st\h7\stm32h723.dtsi:203 */
	};

	/* node '/memory@30004000' defined in zephyr\dts\arm\st\h7\stm32h723.dtsi:207 */
	sram2: memory@30004000 {
		reg = < 0x30004000 0x4000 >;         /* in zephyr\dts\arm\st\h7\stm32h723.dtsi:208 */
		compatible = "zephyr,memory-region",
		             "mmio-sram";            /* in zephyr\dts\arm\st\h7\stm32h723.dtsi:209 */
		zephyr,memory-region = "SRAM2";      /* in zephyr\dts\arm\st\h7\stm32h723.dtsi:210 */
	};

	/* node '/memory@38000000' defined in zephyr\dts\arm\st\h7\stm32h723.dtsi:214 */
	sram4: memory@38000000 {
		reg = < 0x38000000 0x4000 >;         /* in zephyr\dts\arm\st\h7\stm32h723.dtsi:215 */
		compatible = "zephyr,memory-region",
		             "mmio-sram";            /* in zephyr\dts\arm\st\h7\stm32h723.dtsi:216 */
		zephyr,memory-region = "SRAM4";      /* in zephyr\dts\arm\st\h7\stm32h723.dtsi:217 */
	};

	/* node '/memory@20000000' defined in zephyr\dts\arm\st\h7\stm32h723.dtsi:221 */
	dtcm: memory@20000000 {
		compatible = "zephyr,memory-region",
		             "arm,dtcm";             /* in zephyr\dts\arm\st\h7\stm32h723.dtsi:222 */
		reg = < 0x20000000 0x20000 >;        /* in zephyr\dts\arm\st\h7\stm32h723.dtsi:223 */
		zephyr,memory-region = "DTCM";       /* in zephyr\dts\arm\st\h7\stm32h723.dtsi:224 */
	};

	/* node '/memory@0' defined in zephyr\dts\arm\st\h7\stm32h723.dtsi:228 */
	itcm: memory@0 {
		compatible = "zephyr,memory-region",
		             "arm,itcm";             /* in zephyr\dts\arm\st\h7\stm32h723.dtsi:229 */
		reg = < 0x0 0x10000 >;               /* in zephyr\dts\arm\st\h7\stm32h723.dtsi:230 */
		zephyr,memory-region = "ITCM";       /* in zephyr\dts\arm\st\h7\stm32h723.dtsi:231 */
	};

	/* node '/otghs_fs_phy' defined in zephyr\dts\arm\st\h7\stm32h723.dtsi:234 */
	otghs_fs_phy: otghs_fs_phy {
		compatible = "usb-nop-xceiv"; /* in zephyr\dts\arm\st\h7\stm32h723.dtsi:235 */
		#phy-cells = < 0x0 >;         /* in zephyr\dts\arm\st\h7\stm32h723.dtsi:236 */
		phandle = < 0x23 >;           /* in zephyr\dts\arm\st\h7\stm32h723.dtsi:82 */
	};

	/* node '/connector' defined in zephyr\boards\st\nucleo_h723zg\arduino_r3_connector.dtsi:7 */
	arduino_header: connector {
		compatible = "arduino-header-r3";          /* in zephyr\boards\st\nucleo_h723zg\arduino_r3_connector.dtsi:8 */
		#gpio-cells = < 0x2 >;                     /* in zephyr\boards\st\nucleo_h723zg\arduino_r3_connector.dtsi:9 */
		gpio-map-mask = < 0xffffffff 0xffffffc0 >; /* in zephyr\boards\st\nucleo_h723zg\arduino_r3_connector.dtsi:10 */
		gpio-map-pass-thru = < 0x0 0x3f >;         /* in zephyr\boards\st\nucleo_h723zg\arduino_r3_connector.dtsi:11 */
		gpio-map = < 0x0 0x0 &gpioa 0x3 0x0 >,
		           < 0x1 0x0 &gpioc 0x0 0x0 >,
		           < 0x2 0x0 &gpioc 0x3 0x0 >,
		           < 0x3 0x0 &gpiob 0x1 0x0 >,
		           < 0x4 0x0 &gpioc 0x2 0x0 >,
		           < 0x5 0x0 &gpiof 0xa 0x0 >,
		           < 0x6 0x0 &gpiob 0x7 0x0 >,
		           < 0x7 0x0 &gpiob 0x6 0x0 >,
		           < 0x8 0x0 &gpiog 0xe 0x0 >,
		           < 0x9 0x0 &gpioe 0xd 0x0 >,
		           < 0xa 0x0 &gpioe 0xe 0x0 >,
		           < 0xb 0x0 &gpioe 0xb 0x0 >,
		           < 0xc 0x0 &gpioe 0x9 0x0 >,
		           < 0xd 0x0 &gpiog 0xc 0x0 >,
		           < 0xe 0x0 &gpiof 0x3 0x0 >,
		           < 0xf 0x0 &gpiod 0xf 0x0 >,
		           < 0x10 0x0 &gpiod 0xe 0x0 >,
		           < 0x11 0x0 &gpiob 0x5 0x0 >,
		           < 0x12 0x0 &gpioa 0x6 0x0 >,
		           < 0x13 0x0 &gpioa 0x5 0x0 >,
		           < 0x14 0x0 &gpiob 0x9 0x0 >,
		           < 0x15 0x0 &gpiob 0x8 0x0 >;    /* in zephyr\boards\st\nucleo_h723zg\arduino_r3_connector.dtsi:12 */
	};

	/* node '/leds' defined in zephyr\boards\st\nucleo_h723zg\nucleo_h723zg.dts:30 */
	leds: leds {
		compatible = "gpio-leds"; /* in zephyr\boards\st\nucleo_h723zg\nucleo_h723zg.dts:31 */

		/* node '/leds/led_0' defined in zephyr\boards\st\nucleo_h723zg\nucleo_h723zg.dts:33 */
		green_led: led_0 {
			gpios = < &gpiob 0x0 0x0 >; /* in zephyr\boards\st\nucleo_h723zg\nucleo_h723zg.dts:34 */
			label = "User LD1";         /* in zephyr\boards\st\nucleo_h723zg\nucleo_h723zg.dts:35 */
		};

		/* node '/leds/led_1' defined in zephyr\boards\st\nucleo_h723zg\nucleo_h723zg.dts:38 */
		yellow_led: led_1 {
			gpios = < &gpioe 0x1 0x0 >; /* in zephyr\boards\st\nucleo_h723zg\nucleo_h723zg.dts:39 */
			label = "User LD2";         /* in zephyr\boards\st\nucleo_h723zg\nucleo_h723zg.dts:40 */
		};

		/* node '/leds/led_2' defined in zephyr\boards\st\nucleo_h723zg\nucleo_h723zg.dts:43 */
		red_led: led_2 {
			gpios = < &gpiob 0xe 0x0 >; /* in zephyr\boards\st\nucleo_h723zg\nucleo_h723zg.dts:44 */
			label = "User LD3";         /* in zephyr\boards\st\nucleo_h723zg\nucleo_h723zg.dts:45 */
		};
	};

	/* node '/pwmleds' defined in zephyr\boards\st\nucleo_h723zg\nucleo_h723zg.dts:49 */
	pwmleds {
		compatible = "pwm-leds"; /* in zephyr\boards\st\nucleo_h723zg\nucleo_h723zg.dts:50 */

		/* node '/pwmleds/red_pwm_led' defined in zephyr\boards\st\nucleo_h723zg\nucleo_h723zg.dts:52 */
		red_pwm_led: red_pwm_led {
			pwms = < &pwm12 0x1 0x1312d00 0x0 >; /* in zephyr\boards\st\nucleo_h723zg\nucleo_h723zg.dts:53 */
			label = "User LD3 - PWM12";          /* in zephyr\boards\st\nucleo_h723zg\nucleo_h723zg.dts:54 */
		};
	};

	/* node '/gpio_keys' defined in zephyr\boards\st\nucleo_h723zg\nucleo_h723zg.dts:58 */
	gpio_keys {
		compatible = "gpio-keys"; /* in zephyr\boards\st\nucleo_h723zg\nucleo_h723zg.dts:59 */

		/* node '/gpio_keys/button_0' defined in zephyr\boards\st\nucleo_h723zg\nucleo_h723zg.dts:61 */
		user_button: button_0 {
			label = "User";             /* in zephyr\boards\st\nucleo_h723zg\nucleo_h723zg.dts:62 */
			gpios = < &gpioc 0xd 0x0 >; /* in zephyr\boards\st\nucleo_h723zg\nucleo_h723zg.dts:63 */
			zephyr,code = < 0xb >;      /* in zephyr\boards\st\nucleo_h723zg\nucleo_h723zg.dts:64 */
		};
	};
};
